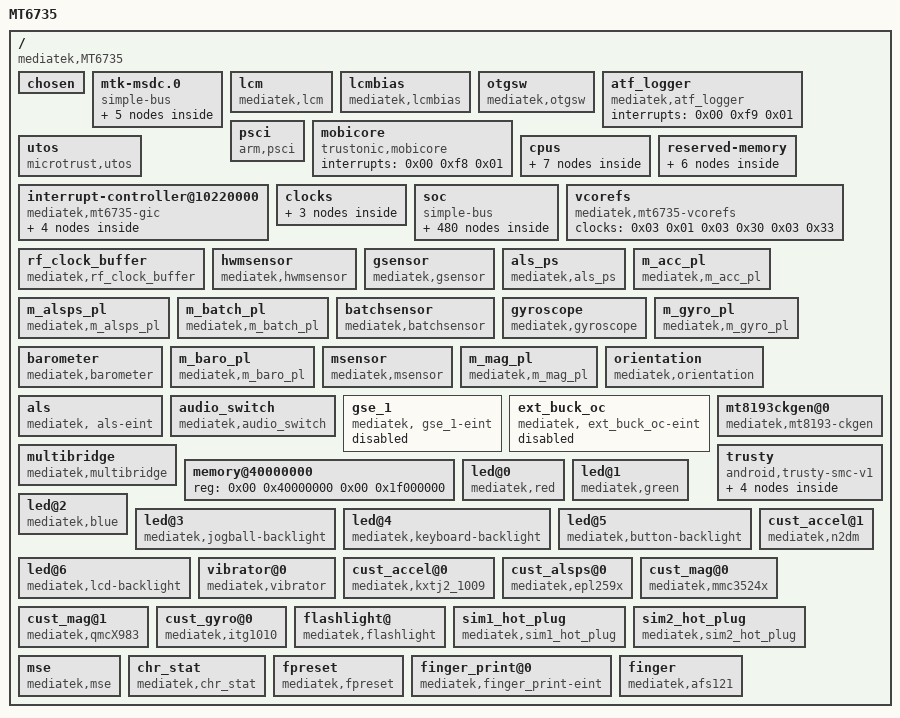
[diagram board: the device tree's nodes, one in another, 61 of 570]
/dts-v1/;

/ {
	model = "MT6735";
	compatible = "mediatek,MT6735";
	interrupt-parent = <0x01>;
	#address-cells = <0x02>;
	#size-cells = <0x02>;

	chosen {
		bootargs = "console=tty0 console=ttyMT0,921600n1 root=/dev/ram initrd=0x44000000,0x300000 loglevel=8 androidboot.hardware=mt6735";
	};

	mtk-msdc.0 {
		compatible = "simple-bus";
		#address-cells = <0x01>;
		#size-cells = <0x01>;
		ranges = <0x00 0x00 0x00 0xffffffff>;

		msdc0@11230000 {
			compatible = "mediatek,mt6735-mmc";
			reg = <0x11230000 0x10000 0x10000e84 0x02>;
			interrupts = <0x00 0x4f 0x08>;
			status = "okay";
			clocks = <0x02 0x0e 0x03 0x0d 0x03 0x29 0x03 0x2b 0x03 0x2c>;
			clock-names = "MSDC0-CLOCK\0MSDC0_PLL_SEL\0MSDC0_PLL_800M\0MSDC0_PLL_400M\0MSDC0_PLL_200M";
			clk_src = [02];
			bus-width = <0x08>;
			max-frequency = <0xbebc200>;
			cap-mmc-highspeed;
			msdc-sys-suspend;
			mmc-ddr-1_8v;
			mmc-hs200-1_8v;
			mmc-hs400-1_8v;
			non-removable;
			pinctl = <0x04>;
			register_setting = <0x05>;
			host_function = [00];
			bootable;
		};

		msdc1@11240000 {
			compatible = "mediatek,mt6735-mmc";
			reg = <0x11240000 0x10000 0x10000e84 0x02>;
			interrupts = <0x00 0x50 0x08>;
			status = "okay";
			clocks = <0x02 0x0f>;
			clock-names = "MSDC1-CLOCK";
			clk_src = [02];
			bus-width = <0x04>;
			max-frequency = <0xbebc200>;
			msdc-sys-suspend;
			cap-sd-highspeed;
			sd-uhs-sdr12;
			sd-uhs-sdr25;
			sd-uhs-sdr50;
			sd-uhs-sdr104;
			sd-uhs-ddr50;
			pinctl = <0x06>;
			pinctl_sdr104 = <0x07>;
			pinctl_sdr50 = <0x08>;
			pinctl_ddr50 = <0x09>;
			register_setting = <0x0a>;
			host_function = [01];
			cd_level = [00];
			cd-gpios = <0x0b 0x05 0x00>;
		};

		msdc2@11250000 {
			compatible = "mediatek,mt6735-mmc";
			reg = <0x11250000 0x10000 0x10000e84 0x02>;
			interrupts = <0x00 0x51 0x08>;
			status = "disabled";
			clocks = <0x02 0x10>;
			clock-names = "MSDC2-CLOCK";
		};

		msdc3@11260000 {
			compatible = "mediatek,mt6735-mmc";
			reg = <0x11260000 0x10000 0x10000e84 0x02>;
			interrupts = <0x00 0x52 0x08>;
			status = "disabled";
			clocks = <0x02 0x11>;
			clock-names = "MSDC3-CLOCK";
		};

		default {
			compatible = "mediatek, msdc1_ins-eint";
			interrupt-parent = <0x0c>;
			interrupts = <0x05 0x08>;
			debounce = <0x05 0x3e8>;
			status = "okay";
		};
	};

	lcm {
		compatible = "mediatek,lcm";
	};

	lcmbias {
		compatible = "mediatek,lcmbias";
		pinctrl-names = "default\0lcd_bias_enp0_gpio\0lcd_bias_enp1_gpio";
		pinctrl-0 = <0x0d>;
		pinctrl-1 = <0x0e>;
		pinctrl-2 = <0x0f>;
		status = "okay";
	};

	otgsw {
		compatible = "mediatek,otgsw";
		pinctrl-names = "default\0otg_switch_enp0_gpio\0otg_switch_enp1_gpio";
		pinctrl-0 = <0x0d>;
		pinctrl-1 = <0x10>;
		pinctrl-2 = <0x11>;
		status = "okay";
	};

	atf_logger {
		compatible = "mediatek,atf_logger";
		interrupts = <0x00 0xf9 0x01>;
	};

	psci {
		compatible = "arm,psci";
		method = "smc";
		cpu_suspend = <0x84000001>;
		cpu_off = <0x84000002>;
		cpu_on = <0x84000003>;
		affinity_info = <0x84000004>;
	};

	mobicore {
		compatible = "trustonic,mobicore";
		interrupts = <0x00 0xf8 0x01>;
	};

	utos {
		compatible = "microtrust,utos";
		interrupts = <0x00 0xf4 0x01 0x00 0xf5 0x01 0x00 0xf6 0x01 0x00 0xfa 0x01 0x00 0xfb 0x01 0x00 0xfc 0x01 0x00 0xfd 0x01 0x00 0xff 0x01>;
	};

	cpus {
		#address-cells = <0x01>;
		#size-cells = <0x00>;

		cpu@000 {
			device_type = "cpu";
			compatible = "arm,cortex-a53";
			reg = <0x00>;
			enable-method = "mt-boot";
			cpu-idle-states = <0x12 0x12 0x13 0x13>;
			cpu-release-addr = <0x00 0x40000200>;
			clock-frequency = "M|m";
			linux,phandle = <0x14>;
			phandle = <0x14>;
		};

		cpu@001 {
			device_type = "cpu";
			compatible = "arm,cortex-a53";
			reg = <0x01>;
			enable-method = "mt-boot";
			cpu-idle-states = <0x12 0x12 0x13 0x13>;
			cpu-release-addr = <0x00 0x40000200>;
			clock-frequency = "M|m";
			linux,phandle = <0x15>;
			phandle = <0x15>;
		};

		cpu@002 {
			device_type = "cpu";
			compatible = "arm,cortex-a53";
			reg = <0x02>;
			enable-method = "mt-boot";
			cpu-idle-states = <0x12 0x12 0x13 0x13>;
			cpu-release-addr = <0x00 0x40000200>;
			clock-frequency = "M|m";
			linux,phandle = <0x16>;
			phandle = <0x16>;
		};

		cpu@003 {
			device_type = "cpu";
			compatible = "arm,cortex-a53";
			reg = <0x03>;
			enable-method = "mt-boot";
			cpu-idle-states = <0x12 0x12 0x13 0x13>;
			cpu-release-addr = <0x00 0x40000200>;
			clock-frequency = "M|m";
			linux,phandle = <0x17>;
			phandle = <0x17>;
		};

		idle-states {
			entry-method = "arm,psci";

			cpu-sleep-0-0 {
				compatible = "arm,idle-state";
				arm,psci-suspend-param = <0x10000>;
				entry-latency-us = <0x258>;
				exit-latency-us = <0x258>;
				min-residency-us = <0x4b0>;
				linux,phandle = <0x13>;
				phandle = <0x13>;
			};

			cluster-sleep-0 {
				compatible = "arm,idle-state";
				arm,psci-suspend-param = <0x1010000>;
				entry-latency-us = <0x320>;
				exit-latency-us = <0x3e8>;
				min-residency-us = <0x7d0>;
				linux,phandle = <0x12>;
				phandle = <0x12>;
			};
		};
	};

	reserved-memory {
		#address-cells = <0x02>;
		#size-cells = <0x02>;
		ranges;

		atf-reserved-memory@43000000 {
			compatible = "mediatek,mt6735-atf-reserved-memory\0mediatek,mt6735m-atf-reserved-memory\0mediatek,mt6753-atf-reserved-memory";
			no-map;
			reg = <0x00 0x43000000 0x00 0x30000>;
		};

		ram_console-reserved-memory@43f00000 {
			compatible = "mediatek,ram_console";
			reg = <0x00 0x43f00000 0x00 0x10000>;
		};

		pstore-reserved-memory@43f10000 {
			compatible = "mediatek,pstore";
			reg = <0x00 0x43f10000 0x00 0xe0000>;
		};

		minirdump-reserved-memory@43ff0000 {
			compatible = "mediatek,minirdump";
			reg = <0x00 0x43ff0000 0x00 0x10000>;
		};

		reserve-memory-ccci_md1 {
			compatible = "mediatek,reserve-memory-ccci_md1";
			no-map;
			size = <0x00 0x3810000>;
			alignment = <0x00 0x2000000>;
			alloc-ranges = <0x00 0x40000000 0x00 0xc0000000>;
		};

		consys-reserve-memory {
			compatible = "mediatek,consys-reserve-memory";
			no-map;
			size = <0x00 0x100000>;
			alignment = <0x00 0x200000>;
		};
	};

	interrupt-controller@10220000 {
		compatible = "mediatek,mt6735-gic";
		#interrupt-cells = <0x03>;
		#address-cells = <0x00>;
		interrupt-controller;
		reg = <0x00 0x10221000 0x00 0x1000 0x00 0x10222000 0x00 0x1000 0x00 0x10200620 0x00 0x1000>;
		mediatek,wdt_irq = <0xa0>;
		linux,phandle = <0x01>;
		phandle = <0x01>;

		gic-cpuif@0 {
			compatible = "arm,gic-cpuif";
			cpuif-id = <0x00>;
			cpu = <0x14>;
		};

		gic-cpuif@1 {
			compatible = "arm,gic-cpuif";
			cpuif-id = <0x01>;
			cpu = <0x15>;
		};

		gic-cpuif@2 {
			compatible = "arm,gic-cpuif";
			cpuif-id = <0x02>;
			cpu = <0x16>;
		};

		gic-cpuif@3 {
			compatible = "arm,gic-cpuif";
			cpuif-id = <0x03>;
			cpu = <0x17>;
		};
	};

	clocks {

		clk_null {
			compatible = "fixed-clock";
			#clock-cells = <0x00>;
			clock-frequency = <0x00>;
		};

		clk26m {
			compatible = "fixed-clock";
			#clock-cells = <0x00>;
			clock-frequency = <0x18cba80>;
			linux,phandle = <0x40>;
			phandle = <0x40>;
		};

		clk32k {
			compatible = "fixed-clock";
			#clock-cells = <0x00>;
			clock-frequency = <0x7d00>;
		};
	};

	soc {
		compatible = "simple-bus";
		#address-cells = <0x01>;
		#size-cells = <0x01>;
		ranges = <0x00 0x00 0x00 0xffffffff>;

		topckgen@10210000 {
			compatible = "mediatek,mt6735-topckgen";
			reg = <0x10210000 0x1000>;
			#clock-cells = <0x01>;
			linux,phandle = <0x03>;
			phandle = <0x03>;
		};

		chipid@08000000 {
			compatible = "mediatek,chipid";
			reg = <0x8000000 0x04 0x8000004 0x04 0x8000008 0x04 0x800000c 0x04>;
		};

		infrasys@10000000 {
			compatible = "mediatek,mt6735-infrasys";
			reg = <0x10000000 0x1000>;
			#clock-cells = <0x01>;
			linux,phandle = <0x1e>;
			phandle = <0x1e>;
		};

		scpsys@10000000 {
			compatible = "mediatek,mt6735-scpsys";
			reg = <0x10000000 0x1000 0x10006000 0x1000>;
			#clock-cells = <0x01>;
			linux,phandle = <0x18>;
			phandle = <0x18>;
		};

		infracfg_ao@10000000 {
			compatible = "mediatek,infracfg_ao";
			reg = <0x10000000 0x1000>;
		};

		usb2jtag@10000000 {
			compatible = "mediatek,usb2jtag_v1";
			reg = <0x10000000 0x1000 0x11210000 0x1000>;
		};

		pwrap@10001000 {
			compatible = "mediatek,PWRAP";
			reg = <0x10001000 0x1000>;
			interrupts = <0x00 0xa3 0x04>;
		};

		perisys@10002000 {
			compatible = "mediatek,mt6735-perisys";
			reg = <0x10002000 0x1000>;
			#clock-cells = <0x01>;
			linux,phandle = <0x02>;
			phandle = <0x02>;
		};

		hacc@10008000 {
			compatible = "mediatek,hacc";
			reg = <0x10008000 0x1000>;
			interrupts = <0x00 0xae 0x08>;
		};

		pericfg@10002000 {
			compatible = "mediatek,pericfg";
			reg = <0x10002000 0x1000>;
		};

		keypad@10003000 {
			compatible = "mediatek,mt6735-keypad";
			reg = <0x10003000 0x1000>;
			interrupts = <0x00 0xa4 0x02>;
			mediatek,kpd-key-debounce = <0x400>;
			mediatek,kpd-sw-pwrkey = <0x74>;
			mediatek,kpd-hw-pwrkey = <0x08>;
			mediatek,kpd-use-extend-type = <0x00>;
			mediatek,kpd-hw-map-num = <0x48>;
			mediatek,kpd-hw-init-map = <0x72 0x73 0x00 0x00 0x00 0x00 0x00 0x00 0x00 0x00 0x00 0x00 0x00 0x00 0x00 0x00 0x00 0x00 0x00 0x00 0x00 0x00 0x00 0x00 0x00 0x00 0x00 0x00 0x00 0x00 0x00 0x00 0x00 0x00 0x00 0x00 0x00 0x00 0x00 0x00 0x00 0x00 0x00 0x00 0x00 0x00 0x00 0x00 0x00 0x00 0x00 0x00 0x00 0x00 0x00 0x00 0x00 0x00 0x00 0x00 0x00 0x00 0x00 0x00 0x00 0x00 0x00 0x00 0x00 0x00 0x00 0x00>;
			mediatek,kpd-pwrkey-eint-gpio = <0x00>;
			mediatek,kpd-pwkey-gpio-din = <0x00>;
			mediatek,kpd-hw-dl-key0 = <0x01>;
			mediatek,kpd-hw-dl-key1 = <0x00>;
			mediatek,kpd-hw-dl-key2 = <0x08>;
			mediatek,kpd-hw-recovery-key = <0x01>;
			mediatek,kpd-hw-factory-key = <0x00>;
			status = "okay";
		};

		apxgpt@10004000 {
			compatible = "mediatek,mt6735-apxgpt";
			reg = <0x10004000 0x1000>;
			interrupts = <0x00 0x98 0x08>;
			clock-frequency = <0xc65d40>;
		};

		eintc@10005000 {
			compatible = "mediatek,mt-eic";
			reg = <0x10005000 0x1000>;
			interrupts = <0x00 0x99 0x04>;
			#interrupt-cells = <0x02>;
			interrupt-controller;
			mediatek,max_eint_num = <0xd5>;
			mediatek,mapping_table_entry = <0x00>;
			mediatek,debtime_setting_entry = <0x0a>;
			mediatek,debtime_setting_array = <0x00 0x7d 0x01 0xfa 0x02 0x1f4 0x03 0x3e8 0x04 0x3e80 0x05 0x7d00 0x06 0xfa00 0x07 0x1f400 0x08 0x3e800 0x09 0x7d000>;
			linux,phandle = <0x0c>;
			phandle = <0x0c>;

			pmic@206 {
				compatible = "mediatek, pmic-eint";
				interrupt-parent = <0x0c>;
				interrupts = <0xce 0x04>;
				debounce = <0xce 0x3e8>;
			};

			MD1_SIM1_HOT_PLUG_EINT@0 {
				compatible = "mediatek,MD1_SIM1_HOT_PLUG_EINT-eint";
				interrupts = <0x00 0x04>;
				debounce = <0x00 0x186a0>;
				dedicated = <0x00 0x00>;
				src_pin = <0x00 0x01>;
				sockettype = <0x00 0x00>;
				status = "okay";
			};

			MD1_SIM2_HOT_PLUG_EINT@1 {
				compatible = "mediatek,MD1_SIM2_HOT_PLUG_EINT-eint";
				interrupts = <0x01 0x04>;
				debounce = <0x01 0x186a0>;
				dedicated = <0x01 0x00>;
				src_pin = <0x01 0x02>;
				sockettype = <0x01 0x00>;
				status = "okay";
			};
		};

		sleep@10006000 {
			compatible = "mediatek,sleep";
			reg = <0x10006000 0x1000>;
			interrupts = <0x00 0xa5 0x08 0x00 0xa6 0x08 0x00 0xa7 0x08 0x00 0xa8 0x08>;
		};

		mdcldma@1000A000 {
			compatible = "mediatek,mdcldma";
			reg = <0x1000a000 0x1000 0x1000b000 0x1000 0x1021a000 0x1000 0x1021b000 0x1000 0x1020a000 0x1000 0x1020b000 0x1000>;
			interrupts = <0x00 0x91 0x04 0x00 0x8c 0x08 0x00 0xdd 0x02>;
			mediatek,md_id = <0x00>;
			mediatek,cldma_capability = <0x06>;
			mediatek,md_smem_size = <0x10000>;
			clocks = <0x18 0x01>;
			clock-names = "scp-sys-md1-main";
			pinctrl-names = "default\0vsram_output_low\0vsram_output_high\0RFIC0_01_mode\0RFIC0_04_mode";
			pinctrl-0 = <0x19>;
			pinctrl-1 = <0x1a>;
			pinctrl-2 = <0x1b>;
			pinctrl-3 = <0x1c>;
			pinctrl-4 = <0x1d>;
		};

		mcucfg@10200000 {
			compatible = "mediatek,mcucfg";
			reg = <0x10200000 0x200>;
			interrupts = <0x00 0x47 0x04>;
		};

		cpuxgpt@10200000 {
			compatible = "mediatek,mt6735-cpuxgpt";
			reg = <0x10200000 0x1000>;
			interrupts = <0x00 0x40 0x04 0x00 0x41 0x04 0x00 0x42 0x04 0x00 0x43 0x04 0x00 0x44 0x04 0x00 0x45 0x04 0x00 0x46 0x04 0x00 0x47 0x04>;
		};

		lastpc@10200000 {
			compatible = "mediatek,mt6735-mcucfg";
			reg = <0x10200000 0x200>;
			interrupts = <0x00 0x47 0x04>;
		};

		emi@10203000 {
			compatible = "mediatek,emi";
			reg = <0x10203000 0x1000>;
			interrupts = <0x00 0x88 0x04>;
		};

		sys_cirq@10204000 {
			compatible = "mediatek,mt6735-sys_cirq";
			reg = <0x10204000 0x1000>;
			interrupts = <0x00 0xe7 0x08>;
			mediatek,cirq_num = <0x9f>;
			mediatek,spi_start_offset = <0x48>;
		};

		m4u@10205000 {
			cell-index = <0x00>;
			compatible = "mediatek,m4u";
			reg = <0x10205000 0x1000>;
			interrupts = <0x00 0x92 0x08>;
			clocks = <0x1e 0x09 0x1f 0x01 0x1f 0x02 0x20 0x01 0x20 0x02 0x21 0x01 0x22 0x02 0x22 0x01>;
			clock-names = "infra_m4u\0smi_common\0m4u_disp0_smi_larb0\0m4u_vdec0_vdec\0m4u_vdec1_larb\0m4u_img_image_larb2_smi\0m4u_venc_venc\0m4u_venc_larb";
		};

		efusec@10206000 {
			compatible = "mediatek,efusec";
			reg = <0x10206000 0x1000>;
		};

		devapc@10207000 {
			compatible = "mediatek,devapc";
			reg = <0x10207000 0x1000>;
			interrupts = <0x00 0x86 0x08>;
			clocks = <0x1e 0x05>;
			clock-names = "devapc-main";
		};

		bus_dbg@10208000 {
			compatible = "mediatek,bus_dbg-v1";
			reg = <0x10208000 0x1000>;
			interrupts = <0x00 0x89 0x08>;
		};

		apmixedsys@10209000 {
			compatible = "mediatek,mt6735-apmixedsys";
			reg = <0x10209000 0x1000>;
			#clock-cells = <0x01>;
			linux,phandle = <0x3f>;
			phandle = <0x3f>;
		};

		apmixed@10209000 {
			compatible = "mediatek,apmixed";
			reg = <0x10209000 0x1000>;
		};

		fhctl@10209f00 {
			compatible = "mediatek,fhctl";
			reg = <0x10209f00 0x100>;
		};

		dramc_nao@1020e000 {
			compatible = "mediatek,mt6735-dramc_nao";
			reg = <0x1020e000 0x1000>;
		};

		cksys@10210000 {
			compatible = "mediatek,cksys";
			reg = <0x10210000 0x1000>;
		};

		syscfg_pctl_a@10211000 {
			compatible = "mediatek,mt6735-pctl-a-syscfg\0syscon";
			reg = <0x00 0x9bceb8 0x00 0x3e8>;
			linux,phandle = <0x23>;
			phandle = <0x23>;
		};

		pinctrl@10211000 {
			compatible = "mediatek,mt6735-pinctrl";
			reg = <0x00 0x9bceb8 0x00 0x3e8>;
			mediatek,pctl-regmap = <0x23>;
			pins-are-numbered;
			gpio-controller;
			#gpio-cells = <0x02>;
			linux,phandle = <0x0b>;
			phandle = <0x0b>;

			8193ckgen_default {
				linux,phandle = <0x97>;
				phandle = <0x97>;
			};

			8193ckgen_gpio {
				linux,phandle = <0x98>;
				phandle = <0x98>;

				pins_cmd_dat {
					pins = <0x00>;
					slew-rate = <0x01>;
					bias-pull-up = <0x00>;
					output-high;
				};
			};

			8193ckgen_dpi {
				linux,phandle = <0x99>;
				phandle = <0x99>;

				pins_cmd_dat {
					pins = <0x02>;
				};
			};

			ssw0default {
				linux,phandle = <0x7c>;
				phandle = <0x7c>;
			};

			ssw@1 {
				linux,phandle = <0x7d>;
				phandle = <0x7d>;

				pins_cmd0_dat {
					pins = <0x805>;
				};

				pins_cmd1_dat {
					pins = <0x904>;
				};
			};

			ssw@2 {
				linux,phandle = <0x7e>;
				phandle = <0x7e>;

				pins_cmd0_dat {
					pins = <0x802>;
				};

				pins_cmd1_dat {
					pins = <0x904>;
				};
			};

			ssw@3 {
				linux,phandle = <0x7f>;
				phandle = <0x7f>;

				pins_cmd0_dat {
					pins = <0xa301>;
					slew-rate = <0x01>;
				};

				pins_cmd1_dat {
					pins = <0xa401>;
					slew-rate = <0x01>;
				};

				pins_cmd2_dat {
					pins = <0xa501>;
					slew-rate = <0x00>;
					bias-pull-up = <0x00>;
				};

				pins_cmd3_dat {
					pins = <0xa001>;
					slew-rate = <0x01>;
				};

				pins_cmd4_dat {
					pins = <0xa101>;
					slew-rate = <0x01>;
				};

				pins_cmd5_dat {
					pins = <0xa201>;
					slew-rate = <0x00>;
					bias-pull-up = <0x00>;
				};
			};

			ssw@4 {
				linux,phandle = <0x80>;
				phandle = <0x80>;

				pins_cmd0_dat {
					pins = <0xa304>;
				};

				pins_cmd1_dat {
					pins = <0xa404>;
				};

				pins_cmd2_dat {
					pins = <0xa504>;
				};

				pins_cmd3_dat {
					pins = <0xa001>;
				};

				pins_cmd4_dat {
					pins = <0xa101>;
				};

				pins_cmd5_dat {
					pins = <0xa201>;
				};
			};

			vsram0default {
				linux,phandle = <0x19>;
				phandle = <0x19>;
			};

			vsram@1 {
				linux,phandle = <0x1a>;
				phandle = <0x1a>;

				pins_cmd_dat {
					pins = <0x8c00>;
					slew-rate = <0x01>;
					output-low;
				};
			};

			vsram@2 {
				linux,phandle = <0x1b>;
				phandle = <0x1b>;

				pins_cmd_dat {
					pins = <0x8c00>;
					slew-rate = <0x01>;
					output-high;
				};
			};

			clockbuf@1 {
				linux,phandle = <0x1c>;
				phandle = <0x1c>;

				pins_cmd0_dat {
					pins = <0x6e01>;
				};

				pins_cmd1_dat {
					pins = <0x6f01>;
				};

				pins_cmd2_dat {
					pins = <0x7001>;
				};

				pins_cmd3_dat {
					pins = <0x7101>;
				};

				pins_cmd4_dat {
					pins = <0x7201>;
				};
			};

			clockbuf@2 {
				linux,phandle = <0x1d>;
				phandle = <0x1d>;

				pins_cmd0_dat {
					pins = <0x6e04>;
				};

				pins_cmd1_dat {
					pins = <0x6f04>;
				};

				pins_cmd2_dat {
					pins = <0x7004>;
				};

				pins_cmd3_dat {
					pins = <0x7104>;
				};

				pins_cmd4_dat {
					pins = <0x7204>;
				};
			};

			uart0gpiodefault {
				linux,phandle = <0x26>;
				phandle = <0x26>;
			};

			uart0_rx_set@gpio74 {
				linux,phandle = <0x27>;
				phandle = <0x27>;

				pins_cmd_dat {
					pins = <0x4a01>;
				};
			};

			uart0_rx_clear@gpio74 {
				linux,phandle = <0x28>;
				phandle = <0x28>;

				pins_cmd_dat {
					pins = <0x4a00>;
					slew-rate = <0x01>;
					output-high;
				};
			};

			uart0_tx_set@gpio75 {
				linux,phandle = <0x29>;
				phandle = <0x29>;

				pins_cmd_dat {
					pins = <0x4b01>;
				};
			};

			uart0_tx_clear@gpio75 {
				linux,phandle = <0x2a>;
				phandle = <0x2a>;

				pins_cmd_dat {
					pins = <0x4b00>;
					slew-rate = <0x01>;
					output-high;
				};
			};

			uart1gpiodefault {
				linux,phandle = <0x2b>;
				phandle = <0x2b>;
			};

			uart1_rx_set@gpio76 {

				pins_cmd_dat {
					pins = <0x4c01>;
				};
			};

			uart1_rx_clear@gpio76 {

				pins_cmd_dat {
					pins = <0x4c00>;
					slew-rate = <0x01>;
					output-high;
				};
			};

			uart1_tx_set@gpio77 {
				linux,phandle = <0x2c>;
				phandle = <0x2c>;

				pins_cmd_dat {
					pins = <0x4d01>;
				};
			};

			uart1_tx_clear@gpio77 {
				linux,phandle = <0x2d>;
				phandle = <0x2d>;

				pins_cmd_dat {
					pins = <0x4d00>;
					slew-rate = <0x01>;
					output-high;
				};
			};

			uart2gpiodefault {
				linux,phandle = <0x2e>;
				phandle = <0x2e>;
			};

			uart2_rx_set@gpio57 {
				linux,phandle = <0x2f>;
				phandle = <0x2f>;

				pins_cmd_dat {
					pins = <0x3901>;
				};
			};

			uart2_rx_clear@gpio57 {
				linux,phandle = <0x30>;
				phandle = <0x30>;

				pins_cmd_dat {
					pins = <0x3900>;
					slew-rate = <0x01>;
					output-high;
				};
			};

			uart2_tx_set@gpio58 {
				linux,phandle = <0x31>;
				phandle = <0x31>;

				pins_cmd_dat {
					pins = <0x3a01>;
				};
			};

			uart2_tx_clear@gpio58 {
				linux,phandle = <0x32>;
				phandle = <0x32>;

				pins_cmd_dat {
					pins = <0x3a00>;
					slew-rate = <0x01>;
					output-high;
				};
			};

			uart3gpiodefault {
				linux,phandle = <0x33>;
				phandle = <0x33>;
			};

			uart3_rx_set@gpio59 {
				linux,phandle = <0x34>;
				phandle = <0x34>;

				pins_cmd_dat {
					pins = <0x3b01>;
				};
			};

			uart3_rx_clear@gpio59 {
				linux,phandle = <0x35>;
				phandle = <0x35>;

				pins_cmd_dat {
					pins = <0x3b00>;
					slew-rate = <0x01>;
					output-high;
				};
			};

			uart3_tx_set@gpio60 {
				linux,phandle = <0x36>;
				phandle = <0x36>;

				pins_cmd_dat {
					pins = <0x3c01>;
				};
			};

			uart3_tx_clear@gpio60 {
				linux,phandle = <0x37>;
				phandle = <0x37>;

				pins_cmd_dat {
					pins = <0x3c00>;
					slew-rate = <0x01>;
					output-high;
				};
			};

			irtx_gpio_led_def@gpio19 {
				linux,phandle = <0x24>;
				phandle = <0x24>;

				pins_cmd_dat {
					pins = <0x1300>;
					slew-rate = <0x01>;
					bias-disable;
					output-high;
					input-schmitt-enable = <0x00>;
				};
			};

			irtx_gpio_led_set@gpio19 {
				linux,phandle = <0x25>;
				phandle = <0x25>;

				pins_cmd_dat {
					pins = <0x1302>;
				};
			};

			alspspincfg {
				linux,phandle = <0x94>;
				phandle = <0x94>;

				pins_cmd_dat {
					pins = <0x4d00>;
					slew-rate = <0x00>;
					bias-pull-up = <0x00>;
				};
			};

			alspsdefaultcfg {
				linux,phandle = <0x93>;
				phandle = <0x93>;
			};

			gyropincfg {
				linux,phandle = <0x96>;
				phandle = <0x96>;

				pins_cmd_dat {
					pins = <0x4300>;
					slew-rate = <0x00>;
					bias-pull-down = <0x00>;
				};
			};

			gyrodefaultcfg {
				linux,phandle = <0x95>;
				phandle = <0x95>;
			};

			eint0default {
				linux,phandle = <0x6d>;
				phandle = <0x6d>;
			};

			eint@0 {
				linux,phandle = <0x6e>;
				phandle = <0x6e>;

				pins_cmd_dat {
					pins = <0xa00>;
					slew-rate = <0x00>;
					bias-pull-up = <0x00>;
				};
			};

			eintoutput0 {
				linux,phandle = <0x6f>;
				phandle = <0x6f>;

				pins_cmd_dat {
					pins = <0xa00>;
					slew-rate = <0x01>;
					output-low;
				};
			};

			eintoutput1 {
				linux,phandle = <0x70>;
				phandle = <0x70>;

				pins_cmd_dat {
					pins = <0xa00>;
					slew-rate = <0x01>;
					output-high;
				};
			};

			rstoutput0 {
				linux,phandle = <0x71>;
				phandle = <0x71>;

				pins_cmd_dat {
					pins = <0x3e00>;
					slew-rate = <0x01>;
					output-low;
				};
			};

			rstoutput1 {
				linux,phandle = <0x72>;
				phandle = <0x72>;

				pins_cmd_dat {
					pins = <0x3e00>;
					slew-rate = <0x01>;
					output-high;
				};
			};

			flashlightdefault {
				linux,phandle = <0x9a>;
				phandle = <0x9a>;
			};

			enableoutput0 {
				linux,phandle = <0x9b>;
				phandle = <0x9b>;

				pins_cmd_dat {
					pins = <0x2a00>;
					slew-rate = <0x01>;
					output-low;
				};
			};

			enableoutput1 {
				linux,phandle = <0x9c>;
				phandle = <0x9c>;

				pins_cmd_dat {
					pins = <0x2a00>;
					slew-rate = <0x01>;
					output-high;
				};
			};

			modeoutput0 {
				linux,phandle = <0x9d>;
				phandle = <0x9d>;

				pins_cmd_dat {
					pins = <0x100>;
					slew-rate = <0x01>;
					output-low;
				};
			};

			modeoutput1 {
				linux,phandle = <0x9e>;
				phandle = <0x9e>;

				pins_cmd_dat {
					pins = <0x100>;
					slew-rate = <0x01>;
					output-high;
				};
			};

			pwmoutput {
				linux,phandle = <0x9f>;
				phandle = <0x9f>;

				pins_cmd_dat {
					pins = <0x101>;
					slew-rate = <0x01>;
				};
			};

			charger_red_GPIO_output {
				linux,phandle = <0xa0>;
				phandle = <0xa0>;

				pins_cmd_dat {
					pins = <0x3900>;
					slew-rate = <0x01>;
					output-high;
				};
			};

			audiodefault {
				linux,phandle = <0x41>;
				phandle = <0x41>;
			};

			pmicclkmode0 {
				linux,phandle = <0x42>;
				phandle = <0x42>;

				pins_cmd0_dat {
					pins = <0x8f00>;
				};

				pins_cmd1_dat {
					pins = <0x9000>;
				};

				pins_cmd2_dat {
					pins = <0x9100>;
				};
			};

			pmicclkmode1 {
				linux,phandle = <0x43>;
				phandle = <0x43>;

				pins_cmd0_dat {
					pins = <0x8f01>;
				};

				pins_cmd1_dat {
					pins = <0x9001>;
				};

				pins_cmd2_dat {
					pins = <0x9101>;
				};
			};

			audi2s1mode0 {
				linux,phandle = <0x44>;
				phandle = <0x44>;

				pins_cmd0_dat {
					pins = <0x4e00>;
				};

				pins_cmd1_dat {
					pins = <0x4f00>;
				};

				pins_cmd2_dat {
					pins = <0x5000>;
				};
			};

			audi2s1mode1 {
				linux,phandle = <0x45>;
				phandle = <0x45>;

				pins_cmd0_dat {
					pins = <0x4e01>;
				};

				pins_cmd1_dat {
					pins = <0x4f01>;
				};

				pins_cmd2_dat {
					pins = <0x5001>;
				};
			};

			audexamphigh {
				linux,phandle = <0x46>;
				phandle = <0x46>;

				pins_cmd_dat {
					pins = <0x8100>;
					slew-rate = <0x01>;
					output-high;
				};
			};

			audexamplow {
				linux,phandle = <0x47>;
				phandle = <0x47>;

				pins_cmd_dat {
					pins = <0x8100>;
					slew-rate = <0x01>;
					output-low;
				};
			};

			audexam2phigh {
				linux,phandle = <0x48>;
				phandle = <0x48>;

				pins_cmd_dat {
					pins = <0x8000>;
					slew-rate = <0x01>;
					output-high;
				};
			};

			audexamp2low {
				linux,phandle = <0x49>;
				phandle = <0x49>;

				pins_cmd_dat {
					pins = <0x8000>;
					slew-rate = <0x01>;
					output-low;
				};
			};

			audrcvspkhigh {
				linux,phandle = <0x4a>;
				phandle = <0x4a>;

				pins_cmd_dat {
					pins = <0x7800>;
					slew-rate = <0x01>;
					output-high;
				};
			};

			audrcvspklow {
				linux,phandle = <0x4b>;
				phandle = <0x4b>;

				pins_cmd_dat {
					pins = <0x7800>;
					slew-rate = <0x01>;
					output-low;
				};
			};

			cam0@0 {
				linux,phandle = <0x5b>;
				phandle = <0x5b>;

				pins_cmd_dat {
					pins = <0x2c00>;
					slew-rate = <0x01>;
					output-low;
				};
			};

			cam0@1 {
				linux,phandle = <0x5c>;
				phandle = <0x5c>;

				pins_cmd_dat {
					pins = <0x2c00>;
					slew-rate = <0x01>;
					output-high;
				};
			};

			cam0@2 {
				linux,phandle = <0x5d>;
				phandle = <0x5d>;

				pins_cmd_dat {
					pins = <0x700>;
					slew-rate = <0x01>;
					output-low;
				};
			};

			cam0@3 {
				linux,phandle = <0x5e>;
				phandle = <0x5e>;

				pins_cmd_dat {
					pins = <0x700>;
					slew-rate = <0x01>;
					output-high;
				};
			};

			cam1@0 {
				linux,phandle = <0x5f>;
				phandle = <0x5f>;

				pins_cmd_dat {
					pins = <0xb00>;
					slew-rate = <0x01>;
					output-low;
				};
			};

			cam1@1 {
				linux,phandle = <0x60>;
				phandle = <0x60>;

				pins_cmd_dat {
					pins = <0xb00>;
					slew-rate = <0x01>;
					output-high;
				};
			};

			cam1@2 {
				linux,phandle = <0x61>;
				phandle = <0x61>;

				pins_cmd_dat {
					pins = <0xc00>;
					slew-rate = <0x01>;
					output-low;
				};
			};

			cam1@3 {
				linux,phandle = <0x62>;
				phandle = <0x62>;

				pins_cmd_dat {
					pins = <0xc00>;
					slew-rate = <0x01>;
					output-high;
				};
			};

			cam@0 {
				linux,phandle = <0x63>;
				phandle = <0x63>;

				pins_cmd_dat {
					pins = <0x4400>;
					slew-rate = <0x01>;
					output-low;
				};
			};

			cam@1 {
				linux,phandle = <0x64>;
				phandle = <0x64>;

				pins_cmd_dat {
					pins = <0x4400>;
					slew-rate = <0x01>;
					output-high;
				};
			};

			camdefault {
				linux,phandle = <0x5a>;
				phandle = <0x5a>;
			};

			default {
				linux,phandle = <0x0d>;
				phandle = <0x0d>;
			};

			gpslna@0 {
				linux,phandle = <0x69>;
				phandle = <0x69>;

				pins_cmd_dat {
					pins = <0x4f00>;
					slew-rate = <0x00>;
					bias-disable;
					output-low;
				};
			};

			gpslna@1 {
				linux,phandle = <0x6a>;
				phandle = <0x6a>;

				pins_cmd_dat {
					pins = <0x4f00>;
					slew-rate = <0x01>;
					output-high;
				};
			};

			gpslna@2 {
				linux,phandle = <0x6b>;
				phandle = <0x6b>;

				pins_cmd_dat {
					pins = <0x4f00>;
					slew-rate = <0x01>;
					output-low;
				};
			};

			mmc0@default {
				linux,phandle = <0x04>;
				phandle = <0x04>;

				pins_cmd {
					drive-strength = [02];
				};

				pins_dat {
					drive-strength = [02];
				};

				pins_clk {
					drive-strength = [02];
				};

				pins_rst {
					drive-strength = [02];
				};

				pins_ds {
					drive-strength = [02];
				};
			};

			mmc0@register_default {
				dat0rddly = [00];
				dat1rddly = [00];
				dat2rddly = [00];
				dat3rddly = [00];
				dat4rddly = [00];
				dat5rddly = [00];
				dat6rddly = [00];
				dat7rddly = [00];
				datwrddly = [00];
				cmdrrddly = [00];
				cmdrddly = [00];
				cmd_edge = [01];
				rdata_edge = [01];
				wdata_edge = [01];
				ett-hs200-cells = <0x0c>;
				ett-hs200-default = <0xb0 0x380 0x00 0xb0 0x7c00 0x00 0xb4 0x38 0x01 0x04 0x02 0x00 0xf0 0x1f0000 0x07 0xf0 0x7c00000 0x0b 0xb4 0x07 0x01 0xf0 0x1f 0x0b 0x04 0x400 0x00 0xf8 0x1f000000 0x07 0xf0 0x1f00 0x09 0x04 0x04 0x00>;
				ett-hs400-cells = <0x08>;
				ett-hs400-default = <0xb0 0x380 0x00 0xb0 0x7c00 0x00 0x188 0x7c 0x02 0x188 0x1f000 0x10 0xb4 0x38 0x01 0x04 0x02 0x00 0xf0 0x1f0000 0x06 0xf0 0x7c00000 0x06>;
				linux,phandle = <0x05>;
				phandle = <0x05>;
			};

			mmc1@default {
				linux,phandle = <0x06>;
				phandle = <0x06>;

				pins_cmd {
					drive-strength = [03];
				};

				pins_dat {
					drive-strength = [03];
				};

				pins_clk {
					drive-strength = [03];
				};
			};

			mmc1@sdr104 {
				linux,phandle = <0x07>;
				phandle = <0x07>;

				pins_cmd {
					drive-strength = [02];
				};

				pins_dat {
					drive-strength = [02];
				};

				pins_clk {
					drive-strength = [03];
				};
			};

			mmc1@sdr50 {
				linux,phandle = <0x08>;
				phandle = <0x08>;

				pins_cmd {
					drive-strength = [02];
				};

				pins_dat {
					drive-strength = [02];
				};

				pins_clk {
					drive-strength = [03];
				};
			};

			mmc1@ddr50 {
				linux,phandle = <0x09>;
				phandle = <0x09>;

				pins_cmd {
					drive-strength = [02];
				};

				pins_dat {
					drive-strength = [02];
				};

				pins_clk {
					drive-strength = [03];
				};
			};

			mmc1@register_default {
				dat0rddly = [00];
				dat1rddly = [00];
				dat2rddly = [00];
				dat3rddly = [00];
				datwrddly = [00];
				cmdrrddly = [00];
				cmdrddly = [00];
				cmd_edge = [01];
				rdata_edge = [01];
				wdata_edge = [01];
				linux,phandle = <0x0a>;
				phandle = <0x0a>;
			};

			state_ven_high {
				linux,phandle = <0x75>;
				phandle = <0x75>;

				pins_cmd_dat {
					pins = <0x400>;
					slew-rate = <0x01>;
					output-high;
				};
			};

			state_ven_low {
				linux,phandle = <0x76>;
				phandle = <0x76>;

				pins_cmd_dat {
					pins = <0x400>;
					slew-rate = <0x01>;
					output-low;
				};
			};

			state_rst_high {
				linux,phandle = <0x77>;
				phandle = <0x77>;

				pins_cmd_dat {
					pins = <0x300>;
					slew-rate = <0x01>;
					output-high;
				};
			};

			state_rst_low {
				linux,phandle = <0x78>;
				phandle = <0x78>;

				pins_cmd_dat {
					pins = <0x300>;
					slew-rate = <0x01>;
					output-low;
				};
			};

			state_eint_high {
				linux,phandle = <0x79>;
				phandle = <0x79>;

				pins_cmd_dat {
					pins = <0x100>;
					slew-rate = <0x01>;
					output-high;
				};
			};

			state_eint_low {
				linux,phandle = <0x7a>;
				phandle = <0x7a>;

				pins_cmd_dat {
					pins = <0x100>;
					slew-rate = <0x01>;
					output-low;
				};
			};

			state_irq_init {
				linux,phandle = <0x7b>;
				phandle = <0x7b>;

				pins_cmd_dat {
					pins = <0x200>;
					slew-rate = <0x00>;
					bias-pull-down = <0x00>;
				};
			};

			usb_default {
				linux,phandle = <0x39>;
				phandle = <0x39>;
			};

			iddig_irq_init {
				linux,phandle = <0x3a>;
				phandle = <0x3a>;

				pins_cmd_dat {
					pins = <0x01>;
					slew-rate = <0x00>;
					bias-pull-up = <0x00>;
				};
			};

			drvvbus_init {
				linux,phandle = <0x3b>;
				phandle = <0x3b>;

				pins_cmd_dat {
					pins = <0x5300>;
					slew-rate = <0x01>;
					bias-pull-down = <0x00>;
				};
			};

			drvvbus_low {
				linux,phandle = <0x3c>;
				phandle = <0x3c>;

				pins_cmd_dat {
					pins = <0x5300>;
					slew-rate = <0x01>;
					output-low;
					bias-pull-down = <0x00>;
				};
			};

			drvvbus_high {
				linux,phandle = <0x3d>;
				phandle = <0x3d>;

				pins_cmd_dat {
					pins = <0x5300>;
					slew-rate = <0x01>;
					output-high;
					bias-pull-down = <0x00>;
				};
			};

			lcm_mode_default {
				linux,phandle = <0x4d>;
				phandle = <0x4d>;

				pins_cmd_dat {
					pins = <0x5000>;
				};
			};

			lcm_mode@0 {
				linux,phandle = <0x4e>;
				phandle = <0x4e>;

				pins_cmd_dat {
					pins = <0x5000>;
				};
			};

			lcm_mode@1 {
				linux,phandle = <0x4f>;
				phandle = <0x4f>;

				pins_cmd_dat {
					pins = <0x5001>;
				};
			};

			lcm_mode@2 {
				linux,phandle = <0x50>;
				phandle = <0x50>;

				pins_cmd_dat {
					pins = <0x5002>;
				};
			};

			lcm_mode@3 {
				linux,phandle = <0x51>;
				phandle = <0x51>;

				pins_cmd_dat {
					pins = <0x5003>;
				};
			};

			lcm_mode@4 {
				linux,phandle = <0x52>;
				phandle = <0x52>;

				pins_cmd_dat {
					pins = <0x5004>;
				};
			};

			lcm_mode@5 {
				linux,phandle = <0x53>;
				phandle = <0x53>;

				pins_cmd_dat {
					pins = <0x5005>;
				};
			};

			lcm_mode@6 {
				linux,phandle = <0x54>;
				phandle = <0x54>;

				pins_cmd_dat {
					pins = <0x5006>;
				};
			};

			lcm_mode@7 {
				linux,phandle = <0x55>;
				phandle = <0x55>;

				pins_cmd_dat {
					pins = <0x5007>;
				};
			};

			lcd_bias_enp0_gpio {
				linux,phandle = <0x0e>;
				phandle = <0x0e>;

				pins_cmd_dat {
					pins = <0x7700>;
					slew-rate = <0x01>;
					output-low;
				};
			};

			lcd_bias_enp1_gpio {
				linux,phandle = <0x0f>;
				phandle = <0x0f>;

				pins_cmd_dat {
					pins = <0x7700>;
					slew-rate = <0x01>;
					output-high;
				};
			};

			otg_switch_enp0_gpio {
				linux,phandle = <0x10>;
				phandle = <0x10>;

				pins_cmd_dat {
					pins = <0x300>;
					slew-rate = <0x01>;
					output-low;
				};
			};

			otg_switch_enp1_gpio {
				linux,phandle = <0x11>;
				phandle = <0x11>;

				pins_cmd_dat {
					pins = <0x300>;
					slew-rate = <0x01>;
					output-high;
				};
			};

			eint6default {
				linux,phandle = <0x73>;
				phandle = <0x73>;
			};

			eint@6 {
				linux,phandle = <0x74>;
				phandle = <0x74>;

				pins_cmd_dat {
					pins = <0x600>;
					slew-rate = <0x00>;
					bias-disable;
				};
			};

			spi_default {
				linux,phandle = <0xa1>;
				phandle = <0xa1>;
			};

			finger_rst_low {
				linux,phandle = <0xa2>;
				phandle = <0xa2>;

				pins_cmd_dat {
					pins = <0x7a00>;
					slew-rate = <0x01>;
					output-low;
				};
			};

			finger_rst_high {
				linux,phandle = <0xa3>;
				phandle = <0xa3>;

				pins_cmd_dat {
					pins = <0x7a00>;
					slew-rate = <0x01>;
					output-high;
				};
			};

			spi_cs_low {
				linux,phandle = <0xa4>;
				phandle = <0xa4>;

				pins_cmd_dat {
					pins = <0x4101>;
					slew-rate = <0x01>;
					output-low;
				};
			};

			spi_cs_high {
				linux,phandle = <0xa5>;
				phandle = <0xa5>;

				pins_cmd_dat {
					pins = <0x4101>;
					slew-rate = <0x01>;
					output-high;
				};
			};

			spi_mi_low {
				linux,phandle = <0xa6>;
				phandle = <0xa6>;

				pins_cmd_dat {
					pins = <0x4301>;
					slew-rate = <0x00>;
					bias-pull-up = <0x00>;
				};
			};

			spi_mi_high {
				linux,phandle = <0xa7>;
				phandle = <0xa7>;

				pins_cmd_dat {
					pins = <0x4301>;
					bias-disable;
				};
			};

			spi_mo_low {
				linux,phandle = <0xa8>;
				phandle = <0xa8>;

				pins_cmd_dat {
					pins = <0x4401>;
					slew-rate = <0x01>;
					output-low;
				};
			};

			spi_mo_high {
				linux,phandle = <0xa9>;
				phandle = <0xa9>;

				pins_cmd_dat {
					pins = <0x4401>;
					slew-rate = <0x01>;
					output-high;
				};
			};

			spi_mclk_low {
				linux,phandle = <0xaa>;
				phandle = <0xaa>;

				pins_cmd_dat {
					pins = <0x4201>;
					slew-rate = <0x01>;
					output-low;
				};
			};

			spi_mclk_high {
				linux,phandle = <0xab>;
				phandle = <0xab>;

				pins_cmd_dat {
					pins = <0x4201>;
					slew-rate = <0x01>;
					output-high;
				};
			};

			eint {
				linux,phandle = <0xac>;
				phandle = <0xac>;

				pins_cmd_dat {
					pins = <0x7900>;
					slew-rate = <0x00>;
					bias-disable;
				};
			};

			eint_in_low {
				linux,phandle = <0xad>;
				phandle = <0xad>;

				pins_cmd_dat {
					pins = <0x7900>;
					slew-rate = <0x00>;
					bias-pull-down = <0x00>;
				};
			};

			eint_in_float {
				linux,phandle = <0xae>;
				phandle = <0xae>;

				pins_cmd_dat {
					pins = <0x7900>;
					slew-rate = <0x00>;
					bias-disable;
				};
			};
		};

		gpio {
			compatible = "mediatek,gpio_usage_mapping";
			GPIO_SIM1_HOT_PLUG = <0x08>;
			GPIO_SIM2_HOT_PLUG = <0x09>;
			GPIO_SIM2_SCLK = <0xa0>;
			GPIO_SIM2_SRST = <0xa1>;
			GPIO_SIM2_SIO = <0xa2>;
			GPIO_SIM1_SCLK = <0xa3>;
			GPIO_SIM1_SRST = <0xa4>;
			GPIO_SIM1_SIO = <0xa5>;
		};

		gpio@10211000 {
			compatible = "mediatek,gpio";
			reg = <0x10211000 0x1000>;
		};

		toprgu@10212000 {
			compatible = "mediatek,mt6735-rgu";
			reg = <0x10212000 0x1000>;
			interrupts = <0x00 0x80 0x02>;
		};

		ddrphy@10213000 {
			compatible = "mediatek,mt6735-ddrphy";
			reg = <0x10213000 0x1000>;
		};

		dramc@10214000 {
			compatible = "mediatek,mt6735-dramc";
			reg = <0x10214000 0x1000>;
			clocks = <0x1e 0x02>;
			clock-names = "infra-cqdma";
		};

		gcpu@10216000 {
			compatible = "mediatek,gcpu";
			reg = <0x10216000 0x1000>;
			interrupts = <0x00 0x96 0x08>;
		};

		gce@10217000 {
			compatible = "mediatek,gce";
			reg = <0x10217000 0x1000>;
			interrupts = <0x00 0x97 0x08 0x00 0x94 0x08>;
			disp_mutex_reg = <0x14014000 0x1000>;
			g3d_config_base = <0x13000000 0x00 0xffff0000>;
			mmsys_config_base = <0x14000000 0x01 0xffff0000>;
			disp_dither_base = <0x14010000 0x02 0xffff0000>;
			mm_na_base = <0x14020000 0x03 0xffff0000>;
			imgsys_base = <0x15000000 0x04 0xffff0000>;
			vdec_gcon_base = <0x16000000 0x05 0xffff0000>;
			venc_gcon_base = <0x17000000 0x06 0xffff0000>;
			conn_peri_base = <0x18000000 0x07 0xffff0000>;
			topckgen_base = <0x10000000 0x08 0xffff0000>;
			kp_base = <0x10010000 0x09 0xffff0000>;
			scp_sram_base = <0x10020000 0x0a 0xffff0000>;
			infra_na3_base = <0x10030000 0x0b 0xffff0000>;
			infra_na4_base = <0x10040000 0x0c 0xffff0000>;
			scp_base = <0x10050000 0x0d 0xffff0000>;
			mcucfg_base = <0x10200000 0x0e 0xffff0000>;
			gcpu_base = <0x10210000 0x0f 0xffff0000>;
			usb0_base = <0x11200000 0x10 0xffff0000>;
			usb_sif_base = <0x11210000 0x11 0xffff0000>;
			audio_base = <0x11220000 0x12 0xffff0000>;
			msdc0_base = <0x11230000 0x13 0xffff0000>;
			msdc1_base = <0x11240000 0x14 0xffff0000>;
			msdc2_base = <0x11250000 0x15 0xffff0000>;
			msdc3_base = <0x11260000 0x16 0xffff0000>;
			pwm_sw_base = <0x1100e000 0x63 0xfffff000>;
			mdp_rdma0_sof = <0x00>;
			mdp_rsz0_sof = <0x01>;
			mdp_rsz1_sof = <0x02>;
			dsi0_te_event = <0x03>;
			mdp_wdma_sof = <0x04>;
			mdp_wrot_sof = <0x05>;
			disp_ovl0_sof = <0x06>;
			disp_rdma0_sof = <0x07>;
			disp_rdma1_sof = <0x08>;
			disp_wdma0_sof = <0x09>;
			disp_ccorr_sof = <0x0a>;
			disp_color_sof = <0x0b>;
			disp_aal_sof = <0x0c>;
			disp_gamma_sof = <0x0d>;
			disp_dither_sof = <0x0e>;
			disp_pwm0_sof = <0x10>;
			mdp_rdma0_frame_done = <0x11>;
			mdp_rsz0_frame_done = <0x12>;
			mdp_rsz1_frame_done = <0x13>;
			mdp_tdshp_frame_done = <0x14>;
			mdp_wdma_frame_done = <0x15>;
			mdp_wrot_write_frame_done = <0x16>;
			mdp_wrot_read_frame_done = <0x17>;
			disp_ovl0_frame_done = <0x18>;
			disp_rdma0_frame_done = <0x19>;
			disp_rdma1_frame_done = <0x1a>;
			disp_wdma0_frame_done = <0x1b>;
			disp_ccorr_frame_done = <0x1c>;
			disp_color_frame_done = <0x1d>;
			disp_aal_frame_done = <0x1e>;
			disp_gamma_frame_done = <0x1f>;
			disp_dither_frame_done = <0x20>;
			disp_dpi0_frame_done = <0x22>;
			stream_done_0 = <0x23>;
			stream_done_1 = <0x24>;
			stream_done_2 = <0x25>;
			stream_done_3 = <0x26>;
			stream_done_4 = <0x27>;
			stream_done_5 = <0x28>;
			stream_done_6 = <0x29>;
			stream_done_7 = <0x2a>;
			stream_done_8 = <0x2b>;
			stream_done_9 = <0x2c>;
			buf_underrun_event_0 = <0x2d>;
			buf_underrun_event_1 = <0x2e>;
			mdp_tdshp_sof = <0x2f>;
			isp_frame_done_p2_2 = <0x41>;
			isp_frame_done_p2_1 = <0x42>;
			isp_frame_done_p2_0 = <0x43>;
			isp_frame_done_p1_1 = <0x44>;
			isp_frame_done_p1_0 = <0x45>;
			camsv_2_pass1_done = <0x46>;
			camsv_1_pass1_done = <0x47>;
			seninf_cam1_2_3_fifo_full = <0x48>;
			seninf_cam0_fifo_full = <0x49>;
			venc_done = <0x81>;
			jpgenc_done = <0x82>;
			jpgdec_done = <0x83>;
			venc_mb_done = <0x84>;
			venc_128byte_cnt_done = <0x85>;
			apxgpt2_count = <0x10004028>;
			clocks = <0x1e 0x02>;
			clock-names = "GCE";
		};

		cqdma@10217c00 {
			compatible = "mediatek,cqdma";
			reg = <0x10217c00 0xc00>;
			interrupts = <0x00 0x97 0x08>;
			nr_channel = <0x01>;
		};

		mcu_biu@10300000 {
			compatible = "mediatek,mt6735-mcu_biu";
			reg = <0x10300000 0x8000>;
		};

		cpu_dbgapb@10810000 {
			compatible = "mediatek,hw_dbg";
			num = <0x04>;
			reg = <0x10810000 0x1000 0x10910000 0x1000 0x10a10000 0x1000 0x10b10000 0x1000>;
		};

		adc_hw@11001000 {
			compatible = "mediatek,mt6735-auxadc";
			reg = <0x11001000 0x1000>;
			interrupts = <0x00 0x4c 0x02>;
			clocks = <0x02 0x1c>;
			clock-names = "auxadc-main";

			adc_channel@ {
				compatible = "mediatek,adc_channel";
				mediatek,temperature0 = <0x00>;
				mediatek,temperature1 = <0x01>;
				mediatek,adc_fdd_rf_params_dynamic_custom_ch = <0x0c>;
				status = "okay";
			};
		};

		dbgapb_base@1011a000 {
			compatible = "mediatek,dbgapb_base";
			reg = <0x1011a000 0x100>;
		};

		dma@11000000 {
			compatible = "mediatek,ap_dma";
			reg = <0x11000000 0x1000>;
			interrupts = <0x00 0x72 0x08>;
		};

		btif_tx@11000880 {
			compatible = "mediatek,btif_tx";
			reg = <0x11000880 0x80>;
			interrupts = <0x00 0x71 0x08>;
		};

		btif_rx@11000900 {
			compatible = "mediatek,btif_rx";
			reg = <0x11000900 0x80>;
			interrupts = <0x00 0x72 0x08>;
		};

		irtx@11011000 {
			compatible = "mediatek,irtx";
			reg = <0x11011000 0x1000>;
			interrupts = <0x00 0x7c 0x04>;
			pwm_ch = <0x00>;
			clock-frequency = <0x18cba80>;
			clock-div = <0x01>;
			clocks = <0x02 0x1e>;
			clock-names = "clk-irtx-main";
			pinctrl-names = "irtx_gpio_default\0irtx_gpio_led_set";
			pinctrl-0 = <0x24>;
			pinctrl-1 = <0x25>;
			status = "okay";
		};

		irtx-pwm {
			compatible = "mediatek,irtx-pwm";
			pwm_ch = <0x02>;
			pwm_data_invert = <0x00>;
		};

		irlearning-spi {
			compatible = "mediatek,irlearning-spi";
			spi_clock = <0x67f3540>;
			spi_data_invert = <0x00>;
			spi_cs_invert = <0x01>;
		};

		apuart0@11002000 {
			cell-index = <0x00>;
			compatible = "mediatek,mt6735-uart";
			reg = <0x11002000 0x1000 0x11000380 0x1000 0x11000400 0x80>;
			interrupts = <0x00 0x5b 0x08 0x00 0x67 0x08 0x00 0x68 0x08>;
			clock-frequency = <0x18cba80>;
			clock-div = <0x01>;
			clocks = <0x02 0x12 0x02 0x0d>;
			clock-names = "uart0-main\0uart-apdma";
			pinctrl-names = "uart0_gpio_default\0uart0_rx_set\0uart0_rx_clear\0uart0_tx_set\0uart0_tx_clear";
			pinctrl-0 = <0x26>;
			pinctrl-1 = <0x27>;
			pinctrl-2 = <0x28>;
			pinctrl-3 = <0x29>;
			pinctrl-4 = <0x2a>;
			status = "okay";
		};

		apuart1@11003000 {
			cell-index = <0x01>;
			compatible = "mediatek,mt6735-uart";
			reg = <0x11003000 0x1000 0x11000480 0x80 0x11000500 0x80>;
			interrupts = <0x00 0x5c 0x08 0x00 0x69 0x08 0x00 0x6a 0x08>;
			clock-frequency = <0x18cba80>;
			clock-div = <0x01>;
			clocks = <0x02 0x13>;
			clock-names = "uart1-main";
			pinctrl-names = "uart1_gpio_default\0uart1_rx_set\0uart1_rx_clear\0uart1_tx_set\0uart1_tx_clear";
			pinctrl-0 = <0x2b>;
			pinctrl-3 = <0x2c>;
			pinctrl-4 = <0x2d>;
			status = "okay";
		};

		apuart2@11004000 {
			cell-index = <0x02>;
			compatible = "mediatek,mt6735-uart";
			reg = <0x11004000 0x1000 0x11000580 0x80 0x11000600 0x80>;
			interrupts = <0x00 0x5d 0x08 0x00 0x6b 0x08 0x00 0x6c 0x08>;
			clock-frequency = <0x18cba80>;
			clock-div = <0x01>;
			clocks = <0x02 0x14>;
			clock-names = "uart2-main";
			pinctrl-names = "uart2_gpio_default\0uart2_rx_set\0uart2_rx_clear\0uart2_tx_set\0uart2_tx_clear";
			pinctrl-0 = <0x2e>;
			pinctrl-1 = <0x2f>;
			pinctrl-2 = <0x30>;
			pinctrl-3 = <0x31>;
			pinctrl-4 = <0x32>;
			status = "okay";
		};

		apuart3@11005000 {
			cell-index = <0x03>;
			compatible = "mediatek,mt6735-uart";
			reg = <0x11005000 0x1000 0x11000680 0x80 0x11000700 0x80>;
			interrupts = <0x00 0x5e 0x08 0x00 0x6d 0x08 0x00 0x6e 0x08>;
			clock-frequency = <0x18cba80>;
			clock-div = <0x01>;
			clocks = <0x02 0x15>;
			clock-names = "uart3-main";
			pinctrl-names = "uart3_gpio_default\0uart3_rx_set\0uart3_rx_clear\0uart3_tx_set\0uart3_tx_clear";
			pinctrl-0 = <0x33>;
			pinctrl-1 = <0x34>;
			pinctrl-2 = <0x35>;
			pinctrl-3 = <0x36>;
			pinctrl-4 = <0x37>;
			status = "okay";
		};

		pwm@11006000 {
			compatible = "mediatek,pwm";
			reg = <0x11006000 0x1000>;
			interrupts = <0x00 0x4d 0x08>;
			clocks = <0x02 0x0a 0x02 0x03 0x02 0x04 0x02 0x05 0x02 0x06 0x02 0x07>;
			clock-names = "PWM-main\0PWM1-main\0PWM2-main\0PWM3-main\0PWM4-main\0PWM5-main";
		};

		devapc_ao@10007000 {
			compatible = "mediatek,devapc_ao";
			reg = <0x10007000 0x1000>;
		};

		i2c@11007000 {
			compatible = "mediatek,mt6735-i2c";
			cell-index = <0x00>;
			reg = <0x11007000 0x1000>;
			interrupts = <0x00 0x54 0x08 0x00 0x63 0x08>;
			def_speed = <0x64>;
			clocks = <0x02 0x18 0x02 0x0d>;
			clock-names = "i2c0-main\0i2c0-dma";
			clock-frequency = <0x3520>;
			clock-div = <0x01>;
			#address-cells = <0x01>;
			#size-cells = <0x00>;

			camera_main@20 {
				compatible = "mediatek,camera_main";
				reg = <0x20>;
				status = "okay";
			};

			camera_main_af@0c {
				compatible = "mediatek,camera_main_af";
				reg = <0x0c>;
				status = "okay";
			};

			camera_sub@6c {
				compatible = "mediatek,camera_sub";
				reg = <0x6c>;
				status = "okay";
			};
		};

		i2c@11008000 {
			compatible = "mediatek,mt6735-i2c";
			cell-index = <0x01>;
			reg = <0x11008000 0x1000>;
			interrupts = <0x00 0x55 0x08 0x00 0x64 0x08>;
			def_speed = <0x64>;
			clocks = <0x02 0x19 0x02 0x0d>;
			clock-names = "i2c1-main\0i2c1-dma";
			clock-frequency = <0x3520>;
			clock-div = <0x01>;
			#address-cells = <0x01>;
			#size-cells = <0x00>;

			cap_touch@48 {
				compatible = "mediatek,cap_touch";
				reg = <0x48>;
				status = "okay";
			};

			i2c_lcd_bias@3e {
				compatible = "mediatek,i2c_lcd_bias";
				reg = <0x3e>;
				status = "okay";
			};

			swithing_charger@36 {
				compatible = "mediatek,swithing_charger";
				reg = <0x36>;
				status = "okay";
			};

			cap_touch1@20 {
				compatible = "mediatek,cap_touch1";
				reg = <0x20>;
				status = "okay";
			};
		};

		spi@1100a000 {
			compatible = "mediatek,mt6735-spi";
			cell-index = <0x00>;
			spi-padmacro = <0x00>;
			reg = <0x1100a000 0x1000>;
			interrupts = <0x00 0x76 0x08>;
			clocks = <0x02 0x1d>;
			clock-names = "spi-main";
			clock-frequency = <0x67f3540>;
			clock-div = <0x01>;
		};

		i2c@11009000 {
			compatible = "mediatek,mt6735-i2c";
			cell-index = <0x02>;
			reg = <0x11009000 0x1000>;
			interrupts = <0x00 0x56 0x08 0x00 0x65 0x08>;
			def_speed = <0x64>;
			clocks = <0x02 0x1a 0x02 0x0d>;
			clock-names = "i2c2-main\0i2c2-dma";
			clock-frequency = <0x3520>;
			clock-div = <0x01>;
			#address-cells = <0x01>;
			#size-cells = <0x00>;

			MSENSOR@2c {
				compatible = "mediatek,MSENSOR_1";
				reg = <0x2c>;
			};

			GSENSOR@08 {
				compatible = "mediatek,GSENSOR_1";
				reg = <0x08>;
			};

			msensor@30 {
				compatible = "mediatek,msensor";
				reg = <0x30>;
				status = "okay";
			};

			gyro@68 {
				compatible = "mediatek,gyro";
				reg = <0x68>;
				status = "okay";
			};

			gsensor@0e {
				compatible = "mediatek,gsensor";
				reg = <0x0e>;
				status = "okay";
			};

			alsps@49 {
				compatible = "mediatek,alsps";
				reg = <0x49>;
				status = "okay";
			};

			strobe_main@63 {
				compatible = "mediatek,strobe_main";
				reg = <0x63>;
				status = "okay";
			};
		};

		therm_ctrl@1100b000 {
			compatible = "mediatek,mt6735-therm_ctrl";
			reg = <0x1100b000 0x1000>;
			interrupts = <0x00 0x4e 0x08>;
			clocks = <0x02 0x02>;
			clock-names = "therm-main";
		};

		ptp_fsm@1100b000 {
			compatible = "mediatek,ptp_fsm_v1";
			reg = <0x1100b000 0x1000>;
			interrupts = <0x00 0x7d 0x08>;
		};

		btif@1100c000 {
			compatible = "mediatek,btif";
			reg = <0x1100c000 0x1000>;
			interrupts = <0x00 0x5a 0x08>;
			clocks = <0x02 0x17 0x02 0x0d>;
			clock-names = "btifc\0apdmac";
		};

		apuart4@1100D000 {
			cell-index = <0x04>;
			compatible = "mediatek,mt6735-uart";
			reg = <0x1100d000 0x1000 0x11000780 0x80 0x11000800 0x80>;
			interrupts = <0x00 0x5f 0x08 0x00 0x6f 0x08 0x00 0x70 0x08>;
			clock-frequency = <0x18cba80>;
			clock-div = <0x01>;
			clocks = <0x02 0x16>;
			clock-names = "uart4-main";
		};

		i2c@1100f000 {
			compatible = "mediatek,mt6735-i2c";
			cell-index = <0x03>;
			reg = <0x1100f000 0x1000>;
			interrupts = <0x00 0x57 0x08 0x00 0x66 0x08>;
			def_speed = <0x64>;
			clocks = <0x02 0x1b 0x02 0x0d>;
			clock-names = "i2c3-main\0i2c3-dma";
			clock-frequency = <0x3520>;
			clock-div = <0x01>;
			#address-cells = <0x01>;
			#size-cells = <0x00>;

			ext_buck@6b {
				compatible = "mediatek,ext_buck";
				reg = <0x6b>;
				status = "okay";
			};
		};

		i2c@11010000 {
			compatible = "mediatek,mt6735-i2c";
			cell-index = <0x04>;
			reg = <0xa7ffd0 0x1000>;
			def_speed = <0x64>;
			clocks = <0x02 0x1b 0x02 0x0d>;
			clock-names = "i2c4-main\0i2c4-dma";
			clock-frequency = <0x3520>;
			clock-div = <0x01>;
		};

		usb20@11200000 {
			compatible = "mediatek,mt6735-usb20";
			cell-index = <0x00>;
			reg = <0x11200000 0x10000 0x11210000 0x10000>;
			interrupts = <0x00 0x48 0x08>;
			mode = <0x02>;
			multipoint = <0x01>;
			num_eps = <0x10>;
			clocks = <0x02 0x0b>;
			clock-names = "usb0";
			vusb33-supply = <0x38>;
			iddig_gpio = <0x00 0x01>;
			drvvbus_gpio = <0x53 0x02>;
			pinctrl-names = "usb_default\0iddig_irq_init\0drvvbus_init\0drvvbus_low\0drvvbus_high";
			pinctrl-0 = <0x39>;
			pinctrl-1 = <0x3a>;
			pinctrl-2 = <0x3b>;
			pinctrl-3 = <0x3c>;
			pinctrl-4 = <0x3d>;
			status = "okay";
		};

		audiosys@11220000 {
			compatible = "mediatek,mt6735-audiosys";
			reg = <0x11220000 0x10000>;
			#clock-cells = <0x01>;
			linux,phandle = <0x3e>;
			phandle = <0x3e>;
		};

		audio@11220000 {
			compatible = "mediatek,audio";
			reg = <0x11220000 0x10000>;
			interrupts = <0x00 0x90 0x08>;
		};

		mt_soc_dl1_pcm@11220000 {
			compatible = "mediatek,mt-soc-dl1-pcm";
			reg = <0x11220000 0x1000>;
			interrupts = <0x00 0x90 0x08>;
			clocks = <0x3e 0x01 0x3e 0x02 0x3e 0x08 0x3e 0x09 0x3e 0x07 0x3e 0x03 0x3e 0x04 0x3e 0x06 0x3e 0x05 0x3e 0x0a 0x1e 0x06 0x03 0x19 0x03 0x1a 0x03 0x21 0x03 0x4b 0x03 0x11 0x03 0x12 0x03 0x33 0x3f 0x08 0x3f 0x09 0x40>;
			clock-names = "aud_afe_clk\0aud_i2s_clk\0aud_dac_clk\0aud_dac_predis_clk\0aud_adc_clk\0aud_apll22m_clk\0aud_apll24m_clk\0aud_apll1_tuner_clk\0aud_apll2_tuner_clk\0aud_tml_clk\0aud_infra_clk\0aud_mux1_clk\0aud_mux2_clk\0top_ad_apll1_clk\0top_whpll_audio_clk\0top_mux_audio\0top_mux_audio_int\0top_sys_pll1_d4\0apmixed_apll1_clk\0apmixed_apll2_clk\0top_clk26m_clk";
			audclk-gpio = <0x8f 0x00>;
			audmiso-gpio = <0x90 0x00>;
			audmosi-gpio = <0x91 0x00>;
			vowclk-gpio = <0x94 0x00>;
			i2s1clk-gpio = <0x50 0x00>;
			i2s1dat-gpio = <0x4e 0x00>;
			i2s1mclk-gpio = <0x09 0x00>;
			i2s1ws-gpio = <0x4f 0x00>;
			pinctrl-names = "default\0audpmicclk-mode0\0audpmicclk-mode1\0audi2s1-mode0\0audi2s1-mode1\0extamp-pullhigh\0extamp-pulllow\0extamp2-pullhigh\0extamp2-pulllow\0rcvspk-pullhigh\0rcvspk-pulllow";
			pinctrl-0 = <0x41>;
			pinctrl-1 = <0x42>;
			pinctrl-2 = <0x43>;
			pinctrl-3 = <0x44>;
			pinctrl-4 = <0x45>;
			pinctrl-5 = <0x46>;
			pinctrl-6 = <0x47>;
			pinctrl-7 = <0x48>;
			pinctrl-8 = <0x49>;
			pinctrl-9 = <0x4a>;
			pinctrl-10 = <0x4b>;
			status = "okay";
			extspkamp-gpio = <0x78 0x00>;
		};

		mfgsys@13000000 {
			compatible = "mediatek,mt6735-mfgsys";
			reg = <0x13000000 0x1000>;
			#clock-cells = <0x01>;
			linux,phandle = <0x4c>;
			phandle = <0x4c>;
		};

		g3d_config@13000000 {
			compatible = "mediatek,g3d_config";
			reg = <0x13000000 0x1000>;
		};

		mali@13040000 {
			compatible = "arm,malit720\0arm,mali-t72x\0arm,malit7xx\0arm,mali-midgard";
			reg = <0x13040000 0x4000>;
			interrupts = <0x00 0xd4 0x08 0x00 0xd3 0x08 0x00 0xd2 0x08>;
			interrupt-names = "JOB\0MMU\0GPU";
			clock-frequency = <0x1ad27480>;
			clocks = <0x4c 0x01 0x1f 0x01 0x18 0x05 0x18 0x04>;
			clock-names = "mfg-main\0mfg-smi-common\0mtcmos-mfg\0mtcmos-display";
		};

		mmsys@14000000 {
			compatible = "mediatek,mt6735-mmsys";
			reg = <0x14000000 0x1000>;
			#clock-cells = <0x01>;
			linux,phandle = <0x1f>;
			phandle = <0x1f>;
		};

		mmsys_config@14000000 {
			compatible = "mediatek,mmsys_config";
			reg = <0x14000000 0x1000>;
			interrupts = <0x00 0xcd 0x08>;
			clocks = <0x1f 0x03>;
			clock-names = "CAM_MDP";
		};

		mdp_rdma@14001000 {
			compatible = "mediatek,mdp_rdma";
			reg = <0x14001000 0x1000>;
			interrupts = <0x00 0xbb 0x08>;
			clocks = <0x1f 0x04>;
			clock-names = "MDP_RDMA";
		};

		mdp_rsz0@14002000 {
			compatible = "mediatek,mdp_rsz0";
			reg = <0x14002000 0x1000>;
			interrupts = <0x00 0xbc 0x08>;
			clocks = <0x1f 0x05>;
			clock-names = "MDP_RSZ0";
		};

		mdp_rsz1@14003000 {
			compatible = "mediatek,mdp_rsz1";
			reg = <0x14003000 0x1000>;
			interrupts = <0x00 0xbd 0x08>;
			clocks = <0x1f 0x06>;
			clock-names = "MDP_RSZ1";
		};

		mdp_wdma@14004000 {
			compatible = "mediatek,mdp_wdma";
			reg = <0x14004000 0x1000>;
			interrupts = <0x00 0xbf 0x08>;
			clocks = <0x1f 0x08>;
			clock-names = "MDP_WDMA";
		};

		mdp_wrot@14005000 {
			compatible = "mediatek,mdp_wrot";
			reg = <0x14005000 0x1000>;
			interrupts = <0x00 0xc0 0x08>;
			clocks = <0x1f 0x09>;
			clock-names = "MDP_WROT";
		};

		mdp_tdshp@14006000 {
			compatible = "mediatek,mdp_tdshp";
			reg = <0x14006000 0x1000>;
			interrupts = <0x00 0xbe 0x08>;
			clocks = <0x1f 0x07>;
			clock-names = "MDP_TDSHP";
		};

		dpi@14012000 {
			compatible = "mediatek,mt6735-dpi";
			reg = <0x14012000 0x1000>;
			interrupts = <0x00 0xcc 0x08>;
		};

		dispsys@14007000 {
			compatible = "mediatek,mt6735-dispsys";
			reg = <0x14007000 0x1000 0x00 0x00 0x14008000 0x1000 0x14009000 0x1000 0x1400a000 0x1000 0x1400b000 0x1000 0x1400c000 0x1000 0x1400d000 0x1000 0x1400e000 0x1000 0x1400f000 0x1000 0x00 0x00 0x1100e000 0x1000 0x00 0x00 0x14014000 0x1000 0x14011000 0x1000 0x14012000 0x1000 0x14000000 0x1000 0x14015000 0x1000 0x14016000 0x1000 0x14017000 0x1000 0x10206000 0x1000 0x10210000 0x1000 0x10211a70 0x0c 0x10211974 0x0c 0x10211b70 0x0c 0x10206044 0x0c 0x10206514 0x0c 0x10206558 0x0c 0x102100a0 0x1000 0x10209270 0x1000 0x10209274 0x1000 0x00 0x00 0x10209000 0x1000>;
			interrupts = <0x00 0xc1 0x08 0x00 0x00 0x08 0x00 0xc2 0x08 0x00 0xc3 0x08 0x00 0xc4 0x08 0x00 0xc5 0x08 0x00 0xc6 0x08 0x00 0xc7 0x08 0x00 0xc8 0x08 0x00 0xc9 0x08 0x00 0x00 0x08 0x00 0x75 0x08 0x00 0x00 0x08 0x00 0xba 0x08 0x00 0xcb 0x08 0x00 0xcc 0x08 0x00 0xcd 0x08 0x00 0xb0 0x08 0x00 0x00 0x08 0x00 0x00 0x08 0x00 0x00 0x08 0x00 0x00 0x08 0x00 0x00 0x08 0x00 0x00 0x08 0x00 0x00 0x08 0x00 0x00 0x08 0x00 0x00 0x08 0x00 0x00 0x08>;
			clocks = <0x1f 0x01 0x1f 0x02 0x1f 0x0b 0x1f 0x0c 0x1f 0x0d 0x1f 0x0e 0x1f 0x0f 0x1f 0x10 0x1f 0x11 0x1f 0x12 0x1f 0x13 0x1f 0x14 0x1f 0x15 0x1f 0x16 0x1f 0x17 0x02 0x01 0x03 0x16 0x3f 0x07 0x03 0x3c 0x03 0x3d 0x03 0x3e 0x03 0x4d 0x03 0x1d 0x03 0x45 0x03 0x3a 0x03 0x22 0x18 0x04>;
			clock-names = "DISP0_SMI_COMMON\0DISP0_SMI_LARB0\0DISP0_DISP_OVL0\0DISP0_DISP_RDMA0\0DISP0_DISP_RDMA1\0DISP0_DISP_WDMA0\0DISP0_DISP_COLOR\0DISP0_DISP_CCORR\0DISP0_DISP_AAL\0DISP0_DISP_GAMMA\0DISP0_DISP_DITHER\0DISP1_DSI_ENGINE\0DISP1_DSI_DIGITAL\0DISP1_DPI_ENGINE\0DISP1_DPI_PIXEL\0DISP_PWM\0MUX_DPI0\0TVDPLL\0TVDPLL_CK\0TVDPLL_D2\0TVDPLL_D4\0DPI_CK\0MUX_DISPPWM\0UNIVPLL2_D4\0SYSPLL4_D2_D8\0AD_SYS_26M_CK\0DISP_MTCMOS_CLK";
		};

		mhl@0 {
			compatible = "mediatek,extd_dev";
		};

		lcm_mode {
			compatible = "mediatek,lcm_mode";
			pinctrl-names = "default\0lcm_mode_00\0lcm_mode_01\0lcm_mode_02\0lcm_mode_03\0lcm_mode_04\0lcm_mode_05\0lcm_mode_06\0lcm_mode_07";
			pinctrl-0 = <0x4d>;
			pinctrl-1 = <0x4e>;
			pinctrl-2 = <0x4f>;
			pinctrl-3 = <0x50>;
			pinctrl-4 = <0x51>;
			pinctrl-5 = <0x52>;
			pinctrl-6 = <0x53>;
			pinctrl-7 = <0x54>;
			pinctrl-8 = <0x55>;
			lcm_power_gpio = <0x0b 0x50 0x00>;
			lcm_bl_gpio = <0x0b 0x81 0x00>;
			status = "okay";
		};

		smi_larb0@14015000 {
			compatible = "mediatek,smi_larb0";
			reg = <0x14015000 0x1000>;
		};

		smi_common@14016000 {
			compatible = "mediatek,smi_common";
			reg = <0x14016000 0x1000 0x14015000 0x1000 0x16010000 0x1000 0x15001000 0x1000 0x17001000 0x1000>;
			clocks = <0x1f 0x01 0x1f 0x02 0x21 0x01 0x20 0x01 0x20 0x02 0x22 0x01 0x22 0x02 0x18 0x08 0x18 0x07 0x18 0x06 0x18 0x04>;
			clock-names = "smi-common\0smi-larb0\0img-larb2\0vdec0-vdec\0vdec1-larb\0venc-larb\0venc-venc\0mtcmos-ven\0mtcmos-vde\0mtcmos-isp\0mtcmos-dis";
		};

		met_smi@14016000 {
			compatible = "mediatek,met_smi";
			reg = <0x14016000 0x1000 0x14015000 0x1000 0x16010000 0x1000 0x15001000 0x1000 0x17001000 0x1000>;
			clocks = <0x1f 0x01 0x1f 0x02 0x21 0x01 0x20 0x01 0x20 0x02 0x22 0x01 0x22 0x02>;
			clock-names = "smi-common\0smi-larb0\0img-larb2\0vdec0-vdec\0vdec1-larb\0venc-larb\0venc-venc";
		};

		imgsys@15000000 {
			compatible = "mediatek,mt6735-imgsys";
			reg = <0x15000000 0x1000>;
			#clock-cells = <0x01>;
			linux,phandle = <0x21>;
			phandle = <0x21>;
		};

		ispsys@15000000 {
			compatible = "mediatek,mt6735-ispsys";
			reg = <0x15004000 0x9000 0x1500d000 0x1000 0x15000000 0x10000 0x10215000 0x3000 0x10211000 0x1000>;
			interrupts = <0x00 0xb7 0x08 0x00 0xb8 0x08 0x00 0xb9 0x08 0x00 0xce 0x08 0x00 0xcf 0x08>;
			clocks = <0x18 0x04 0x18 0x06 0x1f 0x01 0x21 0x02 0x21 0x03 0x21 0x04 0x21 0x05 0x21 0x06 0x21 0x01>;
			clock-names = "CG_SCP_SYS_DIS\0CG_SCP_SYS_ISP\0CG_DISP0_SMI_COMMON\0CG_IMAGE_CAM_SMI\0CG_IMAGE_CAM_CAM\0CG_IMAGE_SEN_TG\0CG_IMAGE_SEN_CAM\0CG_IMAGE_CAM_SV\0CG_IMAGE_LARB2_SMI";
		};

		smi_larb2@15001000 {
			compatible = "mediatek,smi_larb2";
			reg = <0x15001000 0x1000>;
			interrupts = <0x00 0xb2 0x08>;
		};

		kd_camera_hw1@15008000 {
			compatible = "mediatek,camera_hw";
			reg = <0x15008000 0x1000>;
			vcama-supply = <0x56>;
			vcamd-supply = <0x57>;
			vcamaf-supply = <0x58>;
			vcamio-supply = <0x59>;
			clocks = <0x03 0x08 0x03 0x3f 0x03 0x44>;
			clock-names = "TOP_CAMTG_SEL\0TOP_UNIVPLL_D26\0TOP_UNIVPLL2_D2";
			pinctrl-names = "default\0cam0_rst0\0cam0_rst1\0cam0_pnd0\0cam0_pnd1\0cam1_rst0\0cam1_rst1\0cam1_pnd0\0cam1_pnd1\0cam_ldo0_0\0cam_ldo0_1";
			pinctrl-0 = <0x5a>;
			pinctrl-1 = <0x5b>;
			pinctrl-2 = <0x5c>;
			pinctrl-3 = <0x5d>;
			pinctrl-4 = <0x5e>;
			pinctrl-5 = <0x5f>;
			pinctrl-6 = <0x60>;
			pinctrl-7 = <0x61>;
			pinctrl-8 = <0x62>;
			pinctrl-9 = <0x63>;
			pinctrl-10 = <0x64>;
			status = "okay";
			vcama_main2-supply = <0x56>;
			vcama_sub-supply = <0x56>;
			vcamaf_main2-supply = <0x58>;
			vcamaf_sub-supply = <0x58>;
			vcamd_main2-supply = <0x57>;
			vcamd_sub-supply = <0x57>;
			vcamio_main2-supply = <0x59>;
			vcamio_sub-supply = <0x59>;
		};

		kd_camera_hw2@15008000 {
			compatible = "mediatek,camera_hw2";
			reg = <0x15008000 0x1000>;
		};

		fdvt@1500b000 {
			compatible = "mediatek,fdvt";
			reg = <0x1500b000 0x1000>;
			interrupts = <0x00 0xd0 0x08>;
			clocks = <0x18 0x04 0x18 0x06 0x1f 0x01 0x21 0x08>;
			clock-names = "FD-SCP_SYS_DIS\0FD-SCP_SYS_ISP\0FD-MM_DISP0_SMI_COMMON\0FD-IMG_IMAGE_FD";
		};

		vdecsys@16000000 {
			compatible = "mediatek,mt6735-vdecsys";
			reg = <0x16000000 0x1000>;
			interrupts = <0x00 0xb3 0x08>;
			#clock-cells = <0x01>;
			linux,phandle = <0x20>;
			phandle = <0x20>;
		};

		c2k_sdio@0 {
			compatible = "mediatek,mt6735-c2k_sdio";
			interrupts = <0x00 0xe6 0x08>;
		};

		vdec_gcon@16000000 {
			compatible = "mediatek,mt6735-vdec_gcon";
			reg = <0x16000000 0x1000>;
			interrupts = <0x00 0xb3 0x08>;
			clocks = <0x1f 0x01 0x20 0x01 0x20 0x02 0x22 0x02 0x22 0x01 0x03 0x06 0x03 0x32 0x03 0x33 0x18 0x07 0x18 0x08 0x18 0x04>;
			clock-names = "MT_CG_DISP0_SMI_COMMON\0MT_CG_VDEC0_VDEC\0MT_CG_VDEC1_LARB\0MT_CG_VENC_VENC\0MT_CG_VENC_LARB\0MT_CG_TOP_MUX_VDEC\0MT_CG_TOP_SYSPLL1_D2\0MT_CG_TOP_SYSPLL1_D4\0MT_SCP_SYS_VDE\0MT_SCP_SYS_VEN\0MT_SCP_SYS_DIS";
		};

		smi_larb1@16010000 {
			compatible = "mediatek,smi_larb1";
			reg = <0x16010000 0x1000>;
			interrupts = <0x00 0xb1 0x08>;
		};

		vdec@16020000 {
			compatible = "mediatek,mt6735-vdec";
			reg = <0x16020000 0x10000>;
			interrupts = <0x00 0xb3 0x08>;
		};

		vencsys@17000000 {
			compatible = "mediatek,mt6735-vencsys";
			reg = <0x17000000 0x1000>;
			interrupts = <0x00 0xb4 0x08>;
			#clock-cells = <0x01>;
			linux,phandle = <0x22>;
			phandle = <0x22>;
		};

		venc_gcon@17000000 {
			compatible = "mediatek,mt6735-venc_gcon";
			reg = <0x17000000 0x1000>;
			interrupts = <0x00 0xb4 0x08>;
		};

		smi_larb3@17001000 {
			compatible = "mediatek,smi_larb3";
			reg = <0x17001000 0x1000>;
			interrupts = <0x00 0xca 0x08>;
		};

		venc@17002000 {
			compatible = "mediatek,mt6735-venc";
			reg = <0x17002000 0x1000>;
			interrupts = <0x00 0xb4 0x08>;
		};

		jpgenc@17003000 {
			compatible = "mediatek,jpgenc";
			reg = <0x17003000 0x1000>;
			interrupts = <0x00 0xb5 0x08>;
			clocks = <0x18 0x04 0x1f 0x01 0x18 0x08 0x22 0x01 0x22 0x03>;
			clock-names = "disp-mtcmos\0disp-smi\0venc-mtcmos\0venc-larb\0venc-jpgenc";
		};

		jpgdec@17004000 {
			compatible = "mediatek,jpgdec";
			reg = <0x17004000 0x1000>;
			interrupts = <0x00 0xd1 0x08>;
			clocks = <0x18 0x04 0x1f 0x01 0x18 0x08 0x22 0x01 0x22 0x04>;
			clock-names = "disp-mtcmos\0disp-smi\0venc-mtcmos\0venc-larb\0venc-jpgdec";
		};

		consys@18070000 {
			compatible = "mediatek,mt6735-consys";
			reg = <0x18070000 0x200 0x10212000 0x100 0x10000000 0x2000 0x10006000 0x1000>;
			interrupts = <0x00 0xe3 0x08 0x00 0xe1 0x08>;
			clocks = <0x18 0x03 0x1e 0x0b>;
			clock-names = "conn\0bus";
			vcn18-supply = <0x65>;
			vcn28-supply = <0x66>;
			vcn33_bt-supply = <0x67>;
			vcn33_wifi-supply = <0x68>;
			pinctrl-names = "default\0gps_lna_state_init\0gps_lna_state_oh\0gps_lna_state_ol";
			pinctrl-0 = <0x0d>;
			pinctrl-1 = <0x69>;
			pinctrl-2 = <0x6a>;
			pinctrl-3 = <0x6b>;
			status = "okay";
		};

		wifi@180F0000 {
			compatible = "mediatek,wifi";
			reg = <0x180f0000 0x5c>;
			interrupts = <0x00 0xe2 0x08>;
			clocks = <0x02 0x0d>;
			clock-names = "wifi-dma";
		};

		mdc2k@3a00b01c {
			compatible = "mediatek,mdc2k";
			reg = <0x3a00b01c 0x10 0x1021c800 0x300 0x1021d800 0x300>;
			interrupts = <0x00 0xe5 0x02>;
			clocks = <0x18 0x02>;
			clock-names = "scp-sys-md2-main";
		};

		mtkfb@7e000000 {
			compatible = "mediatek,mtkfb";
			reg = <0x7e000000 0x1000000>;
		};

		mt_soc_ul1_pcm {
			compatible = "mediatek,mt_soc_pcm_capture";
		};

		mt_soc_voice_md1 {
			compatible = "mediatek,mt_soc_pcm_voice_md1";
		};

		mt_soc_hdmi_pcm {
			compatible = "mediatek,mt_soc_pcm_hdmi";
		};

		mt_soc_uldlloopback_pcm {
			compatible = "mediatek,mt_soc_pcm_uldlloopback";
		};

		mt_soc_i2s0_pcm {
			compatible = "mediatek,mt_soc_pcm_dl1_i2s0";
		};

		mt_soc_mrgrx_pcm {
			compatible = "mediatek,mt_soc_pcm_mrgrx";
		};

		mt_soc_mrgrx_awb_pcm {
			compatible = "mediatek,mt_soc_pcm_mrgrx_awb";
		};

		mt_soc_fm_i2s_pcm {
			compatible = "mediatek,mt_soc_pcm_fm_i2s";
		};

		mt_soc_fm_i2s_awb_pcm {
			compatible = "mediatek,mt_soc_pcm_fm_i2s_awb";
		};

		mt_soc_i2s0dl1_pcm {
			compatible = "mediatek,mt_soc_pcm_dl1_i2s0Dl1";
		};

		mt_soc_dl1_awb_pcm {
			compatible = "mediatek,mt_soc_pcm_dl1_awb";
		};

		mt_soc_voice_md1_bt {
			compatible = "mediatek,mt_soc_pcm_voice_md1_bt";
		};

		mt_soc_voip_bt_out {
			compatible = "mediatek,mt_soc_pcm_dl1_bt";
		};

		mt_soc_voip_bt_in {
			compatible = "mediatek,mt_soc_pcm_bt_dai";
		};

		mt_soc_tdmrx_pcm {
			compatible = "mediatek,mt_soc_tdm_capture";
		};

		mt_soc_fm_mrgtx_pcm {
			compatible = "mediatek,mt_soc_pcm_fmtx";
		};

		mt_soc_ul2_pcm {
			compatible = "mediatek,mt_soc_pcm_capture2";
		};

		mt_soc_i2s0_awb_pcm {
			compatible = "mediatek,mt_soc_pcm_i2s0_awb";
		};

		mt_soc_voice_md2 {
			compatible = "mediatek,mt_soc_pcm_voice_md2";
		};

		mt_soc_routing_pcm {
			compatible = "mediatek,mt_soc_pcm_routing";
			i2s1clk-gpio = <0x07 0x06>;
			i2s1dat-gpio = <0x05 0x06>;
			i2s1mclk-gpio = <0x09 0x06>;
			i2s1ws-gpio = <0x06 0x06>;
		};

		mt_soc_voice_md2_bt {
			compatible = "mediatek,mt_soc_pcm_voice_md2_bt";
		};

		mt_soc_hp_impedance_pcm {
			compatible = "mediatek,Mt_soc_pcm_hp_impedance";
		};

		mt_soc_codec_name {
			compatible = "mediatek,mt_soc_codec_63xx";
		};

		mt_soc_dummy_pcm {
			compatible = "mediatek,mt_soc_pcm_dummy";
		};

		mt_soc_codec_dummy_name {
			compatible = "mediatek,mt_soc_codec_dummy";
		};

		mt_soc_routing_dai_name {
			compatible = "mediatek,mt_soc_dai_routing";
		};

		mt_soc_dai_name {
			compatible = "mediatek,mt_soc_dai_stub";
		};

		mt_soc_offload_gdma {
			compatible = "mediatek,mt_soc_pcm_offload_gdma";
		};

		mt_soc_dl2_pcm {
			compatible = "mediatek,mt_soc_pcm_dl2";
		};

		touch {
			compatible = "mediatek,mt6735-touch";
			vtouch-supply = <0x6c>;
			tpd-resolution = <0x2d0 0x500>;
			use-tpd-button = <0x00>;
			tpd-key-num = <0x03>;
			tpd-key-local = <0x8b 0xac 0x9e 0x00>;
			tpd-key-dim-local = <0x5a 0x373 0x64 0x28 0xe6 0x373 0x64 0x28 0x172 0x373 0x64 0x28 0x00 0x00 0x00 0x00>;
			tpd-max-touch-num = <0x05>;
			tpd-filter-enable = <0x01>;
			tpd-filter-pixel-density = <0x7c>;
			tpd-filter-custom-prameters = <0x00 0x00 0x00 0x00 0x00 0x00 0x00 0x00 0x00 0x00 0x00 0x00>;
			tpd-filter-custom-speed = <0x00 0x00 0x00>;
			pinctrl-names = "default\0state_eint_as_int\0state_eint_output0\0state_eint_output1\0state_rst_output0\0state_rst_output1";
			pinctrl-0 = <0x6d>;
			pinctrl-1 = <0x6e>;
			pinctrl-2 = <0x6f>;
			pinctrl-3 = <0x70>;
			pinctrl-4 = <0x71>;
			pinctrl-5 = <0x72>;
			status = "okay";
			interrupt-parent = <0x0c>;
			interrupts = <0x0a 0x02>;
			debounce = <0x0a 0x00>;
		};

		hall_1 {
			compatible = "mediatek,hall-eint";
			interrupt-parent = <0x0c>;
			interrupts = <0x02 0x02>;
			debounce = <0x02 0x00>;
			status = "okay";
		};

		accdet {
			compatible = "mediatek,mt6735-accdet";
			accdet-mic-vol = <0x07>;
			headset-mode-setting = <0x500 0x200 0x01 0x1f0 0x800 0x800 0x20>;
			accdet-plugout-debounce = <0x14>;
			accdet-mic-mode = <0x01>;
			headset-three-key-threshold = <0x00 0x50 0xdc 0x1f4>;
			headset-four-key-threshold = <0x00 0x3a 0x79 0xc0 0x1c2>;
			pinctrl-names = "default\0state_eint_as_int";
			pinctrl-0 = <0x73>;
			pinctrl-1 = <0x74>;
			status = "okay";
			interrupt-parent = <0x0c>;
			interrupts = <0x06 0x08>;
			debounce = <0x06 0x3e800>;
		};

		nfc {
			compatible = "mediatek,nfc-gpio-v2";
			gpio-ven = <0x04>;
			gpio-rst = <0x03>;
			gpio-eint = <0x01>;
			gpio-irq = <0x02>;
			pinctrl-names = "default\0ven_high\0ven_low\0rst_high\0rst_low\0eint_high\0eint_low\0irq_init";
			pinctrl-0 = <0x0d>;
			pinctrl-1 = <0x75>;
			pinctrl-2 = <0x76>;
			pinctrl-3 = <0x77>;
			pinctrl-4 = <0x78>;
			pinctrl-5 = <0x79>;
			pinctrl-6 = <0x7a>;
			pinctrl-7 = <0x7b>;
			status = "okay";
		};

		gps {
			compatible = "mediatek,gps";
		};

		simswitch {
			compatible = "mediatek,sim_switch";
			pinctrl-names = "default\0hot_plug_mode1\0hot_plug_mode2\0two_sims_bound_to_md1\0sim1_md3_sim2_md1";
			pinctrl-0 = <0x7c>;
			pinctrl-1 = <0x7d>;
			pinctrl-2 = <0x7e>;
			pinctrl-3 = <0x7f>;
			pinctrl-4 = <0x80>;
		};

		ccci_off {
			compatible = "mediatek,ccci_off";
			clocks = <0x18 0x01>;
			clock-names = "scp-sys-md1-main";
		};

		pmu {
			compatible = "arm,armv8-pmuv3";
			interrupts = <0x00 0x08 0x08 0x00 0x09 0x08 0x00 0x0a 0x08 0x00 0x0b 0x08>;
			interrupt-affinity = <0x14 0x15 0x16 0x17>;
		};

		timer {
			compatible = "arm,armv8-timer";
			interrupts = <0x01 0x0d 0x08 0x01 0x0e 0x08 0x01 0x0b 0x08 0x01 0x0a 0x08>;
			clock-frequency = <0xc65d40>;
		};

		mt_pmic_regulator {
			compatible = "mediatek,mt_pmic";

			buck_regulators {
				compatible = "mediatek,mt_pmic_buck_regulators";

				buck_vpa {
					regulator-name = "vpa";
					regulator-min-microvolt = <0x7a120>;
					regulator-max-microvolt = <0x37b1d0>;
					regulator-ramp-delay = <0xc350>;
					regulator-enable-ramp-delay = <0xb4>;
				};

				buck_vproc {
					regulator-name = "vproc";
					regulator-min-microvolt = <0x927c0>;
					regulator-max-microvolt = <0x154456>;
					regulator-ramp-delay = <0x186a>;
					regulator-enable-ramp-delay = <0xb4>;
					regulator-always-on;
					regulator-boot-on;
				};

				buck_vcore1 {
					regulator-name = "vcore1";
					regulator-min-microvolt = <0x927c0>;
					regulator-max-microvolt = <0x154456>;
					regulator-ramp-delay = <0x186a>;
					regulator-enable-ramp-delay = <0xb4>;
					regulator-always-on;
					regulator-boot-on;
				};

				buck_vsys22 {
					regulator-name = "vsys22";
					regulator-min-microvolt = <0x124f80>;
					regulator-max-microvolt = <0x1e6c16>;
					regulator-ramp-delay = <0x186a>;
					regulator-enable-ramp-delay = <0xb4>;
					regulator-always-on;
					regulator-boot-on;
				};

				buck_vlte {
					regulator-name = "vlte";
					regulator-min-microvolt = <0x927c0>;
					regulator-max-microvolt = <0x154456>;
					regulator-ramp-delay = <0x186a>;
					regulator-enable-ramp-delay = <0xb4>;
					regulator-always-on;
					regulator-boot-on;
				};
			};

			ldo_regulators {
				compatible = "mediatek,mt_pmic_ldo_regulators";

				ldo_vaux18 {
					regulator-name = "vaux18";
					regulator-min-microvolt = <0x1b7740>;
					regulator-max-microvolt = <0x1b7740>;
					regulator-enable-ramp-delay = <0x108>;
					regulator-boot-on;
					linux,phandle = <0x81>;
					phandle = <0x81>;
				};

				ldo_vtcxo_0 {
					regulator-name = "vtcxo_0";
					regulator-min-microvolt = <0x2ab980>;
					regulator-max-microvolt = <0x2ab980>;
					regulator-enable-ramp-delay = <0x6e>;
					regulator-boot-on;
					linux,phandle = <0x82>;
					phandle = <0x82>;
				};

				ldo_vtcxo_1 {
					regulator-name = "vtcxo_1";
					regulator-min-microvolt = <0x2ab980>;
					regulator-max-microvolt = <0x2ab980>;
					regulator-enable-ramp-delay = <0x6e>;
					linux,phandle = <0x83>;
					phandle = <0x83>;
				};

				ldo_vaud28 {
					regulator-name = "vaud28";
					regulator-min-microvolt = <0x2ab980>;
					regulator-max-microvolt = <0x2ab980>;
					regulator-enable-ramp-delay = <0x108>;
					regulator-boot-on;
					linux,phandle = <0x84>;
					phandle = <0x84>;
				};

				ldo_vcn28 {
					regulator-name = "vcn28";
					regulator-min-microvolt = <0x2ab980>;
					regulator-max-microvolt = <0x2ab980>;
					regulator-enable-ramp-delay = <0x108>;
					linux,phandle = <0x66>;
					phandle = <0x66>;
				};

				ldo_vcama {
					regulator-name = "vcama";
					regulator-min-microvolt = <0x16e360>;
					regulator-max-microvolt = <0x2ab980>;
					regulator-enable-ramp-delay = <0x108>;
					regulator-default-on = <0x00>;
					status = "okay";
					linux,phandle = <0x56>;
					phandle = <0x56>;
				};

				ldo_vcn33_bt {
					regulator-name = "vcn33_bt";
					regulator-min-microvolt = <0x325aa0>;
					regulator-max-microvolt = <0x36ee80>;
					regulator-enable-ramp-delay = <0x108>;
					linux,phandle = <0x67>;
					phandle = <0x67>;
				};

				ldo_vcn33_wifi {
					regulator-name = "vcn33_wifi";
					regulator-min-microvolt = <0x325aa0>;
					regulator-max-microvolt = <0x36ee80>;
					regulator-enable-ramp-delay = <0x108>;
					linux,phandle = <0x68>;
					phandle = <0x68>;
				};

				ldo_vusb33 {
					regulator-name = "vusb33";
					regulator-min-microvolt = <0x325aa0>;
					regulator-max-microvolt = <0x325aa0>;
					regulator-enable-ramp-delay = <0x108>;
					regulator-boot-on;
					linux,phandle = <0x38>;
					phandle = <0x38>;
				};

				ldo_vefuse {
					regulator-name = "vefuse";
					regulator-min-microvolt = <0x1b7740>;
					regulator-max-microvolt = <0x2191c0>;
					regulator-enable-ramp-delay = <0x108>;
					linux,phandle = <0x85>;
					phandle = <0x85>;
				};

				ldo_vsim1 {
					regulator-name = "vsim1";
					regulator-min-microvolt = <0x19f0a0>;
					regulator-max-microvolt = <0x200b20>;
					regulator-enable-ramp-delay = <0x108>;
					regulator-default-on = <0x00>;
					status = "okay";
					linux,phandle = <0x86>;
					phandle = <0x86>;
				};

				ldo_vsim2 {
					regulator-name = "vsim2";
					regulator-min-microvolt = <0x19f0a0>;
					regulator-max-microvolt = <0x200b20>;
					regulator-enable-ramp-delay = <0x108>;
					regulator-default-on = <0x00>;
					status = "okay";
					linux,phandle = <0x87>;
					phandle = <0x87>;
				};

				ldo_vemc_3v3 {
					regulator-name = "vemc_3v3";
					regulator-min-microvolt = <0x1b7740>;
					regulator-max-microvolt = <0x325aa0>;
					regulator-enable-ramp-delay = <0x108>;
					regulator-boot-on;
					linux,phandle = <0x88>;
					phandle = <0x88>;
				};

				ldo_vmch {
					regulator-name = "vmch";
					regulator-min-microvolt = <0x2c4020>;
					regulator-max-microvolt = <0x325aa0>;
					regulator-enable-ramp-delay = <0x2c>;
					linux,phandle = <0x89>;
					phandle = <0x89>;
				};

				ldo_vtref {
					regulator-name = "vtref";
					regulator-min-microvolt = <0x1b7740>;
					regulator-max-microvolt = <0x1b7740>;
					regulator-enable-ramp-delay = <0xf0>;
					linux,phandle = <0x8a>;
					phandle = <0x8a>;
				};

				ldo_vmc {
					regulator-name = "vmc";
					regulator-min-microvolt = <0x1b7740>;
					regulator-max-microvolt = <0x325aa0>;
					regulator-enable-ramp-delay = <0x2c>;
					linux,phandle = <0x8b>;
					phandle = <0x8b>;
				};

				ldo_vcamaf {
					regulator-name = "vcamaf";
					regulator-min-microvolt = <0x124f80>;
					regulator-max-microvolt = <0x325aa0>;
					regulator-enable-ramp-delay = <0x108>;
					regulator-default-on = <0x00>;
					status = "okay";
					linux,phandle = <0x58>;
					phandle = <0x58>;
				};

				ldo_vio28 {
					regulator-name = "vio28";
					regulator-min-microvolt = <0x2ab980>;
					regulator-max-microvolt = <0x2ab980>;
					regulator-enable-ramp-delay = <0x108>;
					regulator-boot-on;
					linux,phandle = <0x8c>;
					phandle = <0x8c>;
				};

				ldo_vgp1 {
					regulator-name = "vgp1";
					regulator-min-microvolt = <0x124f80>;
					regulator-max-microvolt = <0x325aa0>;
					regulator-enable-ramp-delay = <0x108>;
					regulator-default-on = <0x00>;
					status = "okay";
					linux,phandle = <0x6c>;
					phandle = <0x6c>;
				};

				ldo_vibr {
					regulator-name = "vibr";
					regulator-min-microvolt = <0x124f80>;
					regulator-max-microvolt = <0x325aa0>;
					regulator-enable-ramp-delay = <0x2c>;
					regulator-default-on = <0x00>;
					status = "okay";
					linux,phandle = <0x8d>;
					phandle = <0x8d>;
				};

				ldo_vcamd {
					regulator-name = "vcamd";
					regulator-min-microvolt = <0xdbba0>;
					regulator-max-microvolt = <0x16e360>;
					regulator-enable-ramp-delay = <0x108>;
					regulator-default-on = <0x00>;
					status = "okay";
					linux,phandle = <0x57>;
					phandle = <0x57>;
				};

				ldo_vrf18_0 {
					regulator-name = "vrf18_0";
					regulator-min-microvolt = <0x1bd8e8>;
					regulator-max-microvolt = <0x1bd8e8>;
					regulator-enable-ramp-delay = <0xdc>;
					linux,phandle = <0x8e>;
					phandle = <0x8e>;
				};

				ldo_vrf18_1 {
					regulator-name = "vrf18_1";
					regulator-min-microvolt = <0x124f80>;
					regulator-max-microvolt = <0x1bd8e8>;
					regulator-enable-ramp-delay = <0xdc>;
					linux,phandle = <0x8f>;
					phandle = <0x8f>;
				};

				ldo_vio18 {
					regulator-name = "vio18";
					regulator-min-microvolt = <0x1b7740>;
					regulator-max-microvolt = <0x1b7740>;
					regulator-enable-ramp-delay = <0x108>;
					regulator-boot-on;
					linux,phandle = <0x90>;
					phandle = <0x90>;
				};

				ldo_vcn18 {
					regulator-name = "vcn18";
					regulator-min-microvolt = <0x1b7740>;
					regulator-max-microvolt = <0x1b7740>;
					regulator-enable-ramp-delay = <0x2c>;
					linux,phandle = <0x65>;
					phandle = <0x65>;
				};

				ldo_vcamio {
					regulator-name = "vcamio";
					regulator-min-microvolt = <0x124f80>;
					regulator-max-microvolt = <0x1b7740>;
					regulator-enable-ramp-delay = <0xdc>;
					regulator-default-on = <0x00>;
					status = "okay";
					linux,phandle = <0x59>;
					phandle = <0x59>;
				};

				ldo_vsram {
					regulator-name = "vsram";
					regulator-min-microvolt = <0xaae60>;
					regulator-max-microvolt = <0x16caf6>;
					regulator-enable-ramp-delay = <0xdc>;
					regulator-ramp-delay = <0x186a>;
					regulator-boot-on;
					linux,phandle = <0x91>;
					phandle = <0x91>;
				};

				ldo_vm {
					regulator-name = "vm";
					regulator-min-microvolt = <0x12ebc0>;
					regulator-max-microvolt = <0x177fa0>;
					regulator-enable-ramp-delay = <0x108>;
					regulator-boot-on;
					linux,phandle = <0x92>;
					phandle = <0x92>;
				};
			};

			regulators_supply {
				compatible = "mediatek,mt_pmic_regulator_supply";
				vaux18-supply = <0x81>;
				vtcxo_0-supply = <0x82>;
				vtcxo_1-supply = <0x83>;
				vaud28-supply = <0x84>;
				vefuse-supply = <0x85>;
				vsim1-supply = <0x86>;
				vsim2-supply = <0x87>;
				vemc_3v3-supply = <0x88>;
				vmch-supply = <0x89>;
				vtref-supply = <0x8a>;
				vmc-supply = <0x8b>;
				vio28-supply = <0x8c>;
				vibr-supply = <0x8d>;
				vrf18_0-supply = <0x8e>;
				vrf18_1-supply = <0x8f>;
				vio18-supply = <0x90>;
				vsram-supply = <0x91>;
				vm-supply = <0x92>;
			};
		};

		btcvsd@10000000 {
			compatible = "mediatek,audio_bt_cvsd";
			offset = <0x700 0x800 0xfd0 0xfd4 0xfd8>;
			reg = <0x10000000 0x1000 0x18000000 0x10000 0x18080000 0x8000>;
			interrupts = <0x00 0xe4 0x08>;
		};

		bat_meter {
			compatible = "mediatek,bat_meter";
			r_bat_sense = <0x04>;
			r_i_sense = <0x04>;
			r_charger_1 = <0x14a>;
			r_charger_2 = <0x27>;
			temperature_t0 = <0x6e>;
			temperature_t1 = <0x00>;
			temperature_t2 = <0x19>;
			temperature_t3 = <0x32>;
			temperature_t = <0xff>;
			fg_meter_resistance = <0x00>;
			q_max_pos_50 = <0xf33>;
			q_max_pos_25 = <0xeba>;
			q_max_pos_0 = <0xe0a>;
			q_max_neg_10 = <0xd17>;
			q_max_pos_50_h_current = <0xefe>;
			q_max_pos_25_h_current = <0xea0>;
			q_max_pos_0_h_current = <0xd7c>;
			q_max_neg_10_h_current = <0x764>;
			oam_d5 = <0x01>;
			change_tracking_point = <0x01>;
			cust_tracking_point = <0x01>;
			cust_r_sense = <0x21>;
			cust_hw_cc = <0x00>;
			aging_tuning_value = <0x67>;
			cust_r_fg_offset = <0x00>;
			ocv_board_compesate = <0x00>;
			r_fg_board_base = <0x3e8>;
			r_fg_board_slope = <0x3e8>;
			car_tune_value = <0x4d>;
			current_detect_r_fg = <0x0a>;
			minerroroffset = <0x3e8>;
			fg_vbat_average_size = <0x12>;
			r_fg_value = <0x0a>;
			cust_poweron_delta_capacity_tolrance = <0x28>;
			cust_poweron_low_capacity_tolrance = <0x05>;
			cust_poweron_max_vbat_tolrance = <0x5a>;
			cust_poweron_delta_vbat_tolrance = <0x1e>;
			cust_poweron_delta_hw_sw_ocv_capacity_tolrance = <0x0a>;
			fixed_tbat_25 = <0x00>;
			vbat_normal_wakeup = <0xe10>;
			vbat_low_power_wakeup = <0xdac>;
			normal_wakeup_period = <0x1518>;
			low_power_wakeup_period = <0x12c>;
			close_poweroff_wakeup_period = <0x1e>;
			rbat_pull_up_r = <0xf1cc>;
			rbat_pull_up_volt = <0x708>;
			batt_temperature_table_num = <0x11>;
			batt_temperature_table = <0xffffffec 0x5ec3a 0xfffffff1 0x58192 0xfffffff6 0x42551 0xfffffffb 0x3267f 0x00 0x26a06 0x05 0x1dd93 0x0a 0x173fb 0x0f 0x123ea 0x14 0xe6b9 0x19 0xb798 0x1e 0x930b 0x23 0x767e 0x28 0x600f 0x2d 0x4e50 0x32 0x4031 0x37 0x34e3 0x3c 0x2bca>;
			battery_profile_t0_num = <0x56>;
			battery_profile_t0 = <0x00 0x1128 0x01 0x1114 0x03 0x10ff 0x04 0x10ed 0x06 0x10da 0x07 0x10c8 0x09 0x10b6 0x0a 0x10a5 0x0c 0x1091 0x0d 0x107a 0x0f 0x105d 0x10 0x103f 0x12 0x1023 0x13 0x1011 0x15 0x1003 0x16 0xff6 0x18 0xfe8 0x19 0xfd7 0x1b 0xfc4 0x1c 0xfb1 0x1e 0xf9f 0x1f 0xf90 0x21 0xf82 0x22 0xf75 0x24 0xf68 0x25 0xf5d 0x27 0xf51 0x28 0xf46 0x2a 0xf3b 0x2b 0xf31 0x2d 0xf28 0x2e 0xf1f 0x30 0xf17 0x31 0xf10 0x33 0xf09 0x34 0xf02 0x36 0xefc 0x37 0xef6 0x39 0xef0 0x3a 0xeeb 0x3c 0xee6 0x3d 0xee2 0x3f 0xede 0x40 0xeda 0x42 0xed7 0x43 0xed3 0x45 0xed0 0x46 0xecd 0x48 0xec9 0x49 0xec5 0x4b 0xec1 0x4c 0xebd 0x4e 0xeb8 0x4f 0xeb3 0x51 0xead 0x52 0xea7 0x54 0xea1 0x55 0xe99 0x56 0xe91 0x57 0xe8a 0x58 0xe85 0x59 0xe81 0x5a 0xe7e 0x5b 0xe79 0x5c 0xe75 0x5d 0xe73 0x5e 0xe71 0x5f 0xe6e 0x60 0xe6a 0x61 0xe64 0x62 0xe5d 0x63 0xe4c 0x64 0xd48 0x64 0xd48 0x64 0xd48 0x64 0xd48 0x64 0xd48 0x64 0xd48 0x64 0xd48 0x64 0xd48 0x64 0xd48 0x64 0xd48 0x64 0xd48 0x64 0xd48 0x64 0xd48 0x64 0xd48>;
			battery_profile_t1_num = <0x56>;
			battery_profile_t1 = <0x00 0x1129 0x01 0x1118 0x03 0x1103 0x04 0x10f2 0x06 0x10e2 0x07 0x10d3 0x08 0x10c4 0x0a 0x10b5 0x0b 0x10a7 0x0d 0x1099 0x0e 0x108b 0x0f 0x107c 0x11 0x106e 0x12 0x1060 0x13 0x1052 0x15 0x1045 0x16 0x1037 0x18 0x102a 0x19 0x101c 0x1a 0x100e 0x1c 0x1000 0x1d 0xff4 0x1f 0xfe7 0x20 0xfda 0x21 0xfc8 0x23 0xfb3 0x24 0xf9d 0x26 0xf89 0x27 0xf78 0x28 0xf6b 0x2a 0xf60 0x2b 0xf58 0x2d 0xf4f 0x2e 0xf47 0x2f 0xf3f 0x31 0xf37 0x32 0xf2f 0x33 0xf27 0x35 0xf20 0x36 0xf18 0x38 0xf12 0x39 0xf0b 0x3a 0xf04 0x3c 0xefe 0x3d 0xef8 0x3f 0xef2 0x40 0xeec 0x41 0xee6 0x43 0xee1 0x44 0xedb 0x46 0xed6 0x47 0xed0 0x48 0xecb 0x4a 0xec6 0x4b 0xec0 0x4d 0xebb 0x4e 0xeb6 0x4f 0xeb0 0x51 0xea9 0x52 0xea3 0x53 0xe9b 0x55 0xe93 0x56 0xe8b 0x58 0xe81 0x59 0xe7b 0x5a 0xe77 0x5c 0xe74 0x5d 0xe72 0x5f 0xe6e 0x60 0xe65 0x61 0xe46 0x63 0xe0b 0x64 0xd48 0x64 0xd48 0x64 0xd48 0x64 0xd48 0x64 0xd48 0x64 0xd48 0x64 0xd48 0x64 0xd48 0x64 0xd48 0x64 0xd48 0x64 0xd48 0x64 0xd48 0x64 0xd48 0x64 0xd48>;
			battery_profile_t2_num = <0x56>;
			battery_profile_t2 = <0x00 0x110d 0x01 0x110c 0x02 0x10fd 0x04 0x10ee 0x05 0x10e0 0x06 0x10d1 0x07 0x10c3 0x09 0x10b4 0x0a 0x10a6 0x0b 0x1097 0x0c 0x108a 0x0d 0x107c 0x0f 0x106d 0x10 0x105e 0x11 0x1052 0x12 0x1044 0x14 0x1035 0x15 0x1026 0x16 0x101a 0x17 0x100c 0x18 0xfff 0x1a 0xff2 0x1b 0xfe5 0x1c 0xfdc 0x1d 0xfcf 0x1e 0xfc3 0x20 0xfb7 0x21 0xfaa 0x22 0xf9f 0x23 0xf94 0x25 0xf8a 0x26 0xf82 0x27 0xf79 0x28 0xf6f 0x29 0xf63 0x2b 0xf57 0x2c 0xf48 0x2d 0xf38 0x2e 0xf2b 0x30 0xf21 0x31 0xf19 0x32 0xf12 0x33 0xf0a 0x34 0xf04 0x36 0xefd 0x37 0xef9 0x38 0xef3 0x39 0xeee 0x3b 0xee9 0x3c 0xee5 0x3d 0xede 0x3e 0xedb 0x3f 0xed7 0x41 0xed4 0x42 0xed1 0x43 0xece 0x44 0xecb 0x45 0xec8 0x47 0xec5 0x48 0xec1 0x49 0xebc 0x4a 0xeb6 0x4c 0xeb1 0x4d 0xead 0x4e 0xea9 0x4f 0xea3 0x50 0xea0 0x52 0xe9c 0x53 0xe97 0x54 0xe8f 0x55 0xe86 0x57 0xe80 0x58 0xe78 0x59 0xe6e 0x5a 0xe6b 0x5b 0xe69 0x5d 0xe68 0x5e 0xe66 0x5f 0xe62 0x60 0xe46 0x62 0xe0e 0x63 0xdbd 0x64 0xd48 0x64 0xd48 0x64 0xd48 0x64 0xd48>;
			battery_profile_t3_num = <0x56>;
			battery_profile_t3 = <0x00 0x1129 0x01 0x1126 0x02 0x1110 0x04 0x10ff 0x05 0x10ef 0x06 0x10e0 0x07 0x10d2 0x08 0x10c4 0x09 0x10b5 0x0b 0x10a7 0x0c 0x1099 0x0d 0x108b 0x0e 0x107d 0x0f 0x106f 0x11 0x1061 0x12 0x1053 0x13 0x1045 0x14 0x1038 0x15 0x102a 0x16 0x101d 0x18 0x1010 0x19 0x1003 0x1a 0xff5 0x1b 0xfea 0x1c 0xfdd 0x1e 0xfd1 0x1f 0xfc6 0x20 0xfba 0x21 0xfae 0x22 0xfa3 0x23 0xf99 0x25 0xf8f 0x26 0xf85 0x27 0xf7b 0x28 0xf72 0x29 0xf68 0x2b 0xf5f 0x2c 0xf55 0x2d 0xf49 0x2e 0xf3a 0x2f 0xf2a 0x30 0xf1f 0x32 0xf15 0x33 0xf0e 0x34 0xf07 0x35 0xf01 0x36 0xefb 0x38 0xef4 0x39 0xeef 0x3a 0xeea 0x3b 0xee5 0x3c 0xee1 0x3d 0xedc 0x3f 0xed8 0x40 0xed4 0x41 0xed0 0x42 0xecd 0x43 0xeca 0x45 0xec7 0x46 0xec3 0x47 0xec0 0x48 0xebc 0x49 0xeb6 0x4a 0xeac 0x4c 0xea6 0x4d 0xea2 0x4e 0xe9e 0x4f 0xe99 0x50 0xe94 0x52 0xe90 0x53 0xe8c 0x54 0xe87 0x55 0xe80 0x56 0xe77 0x58 0xe70 0x59 0xe67 0x5a 0xe5e 0x5b 0xe5d 0x5c 0xe5c 0x5d 0xe5b 0x5f 0xe59 0x60 0xe53 0x61 0xe36 0x62 0xdff 0x63 0xdb2 0x64 0xd48>;
			r_profile_t0_num = <0x56>;
			r_profile_t0 = <0x36e 0x1128 0x36e 0x1114 0x385 0x10ff 0x390 0x10ed 0x395 0x10da 0x39a 0x10c8 0x39d 0x10b6 0x3a7 0x10a5 0x3b8 0x1091 0x3dd 0x107a 0x408 0x105d 0x43d 0x103f 0x44f 0x1023 0x44f 0x1011 0x451 0x1003 0x456 0xff6 0x458 0xfe8 0x456 0xfd7 0x44c 0xfc4 0x444 0xfb1 0x43d 0xf9f 0x43b 0xf90 0x43c 0xf82 0x438 0xf75 0x434 0xf68 0x430 0xf5d 0x42a 0xf51 0x426 0xf46 0x428 0xf3b 0x41f 0xf31 0x41e 0xf28 0x419 0xf1f 0x41a 0xf17 0x41c 0xf10 0x41d 0xf09 0x41e 0xf02 0x424 0xefc 0x426 0xef6 0x427 0xef0 0x42b 0xeeb 0x431 0xee6 0x43b 0xee2 0x444 0xede 0x44b 0xeda 0x455 0xed7 0x460 0xed3 0x46c 0xed0 0x478 0xecd 0x481 0xec9 0x48f 0xec5 0x49b 0xec1 0x4ab 0xebd 0x4bb 0xeb8 0x4cd 0xeb3 0x4de 0xead 0x4f3 0xea7 0x508 0xea1 0x51f 0xe99 0x52a 0xe91 0x518 0xe8a 0x50d 0xe85 0x503 0xe81 0x4fb 0xe7e 0x4ee 0xe79 0x4e5 0xe75 0x4df 0xe73 0x4da 0xe71 0x4d3 0xe6e 0x4ca 0xe6a 0x4b9 0xe64 0x4a7 0xe5d 0x47d 0xe4c 0x406 0xe1c 0x406 0xe1c 0x406 0xe1c 0x406 0xe1c 0x406 0xe1c 0x406 0xe1c 0x406 0xe1c 0x406 0xe1c 0x406 0xe1c 0x406 0xe1c 0x406 0xe1c 0x406 0xe1c 0x406 0xe1c 0x406 0xe1c>;
			r_profile_t1_num = <0x56>;
			r_profile_t1 = <0x1f7 0x1129 0x1f7 0x1118 0x1f2 0x1103 0x1f4 0x10f2 0x1f6 0x10e2 0x1f6 0x10d3 0x1f6 0x10c4 0x1f6 0x10b5 0x1f6 0x10a7 0x1f7 0x1099 0x1f6 0x108b 0x1f6 0x107c 0x1f6 0x106e 0x1f6 0x1060 0x1f8 0x1052 0x1f9 0x1045 0x1fa 0x1037 0x1fc 0x102a 0x1fc 0x101c 0x1fc 0x100e 0x1fb 0x1000 0x1fc 0xff4 0x200 0xfe7 0x204 0xfda 0x203 0xfc8 0x1f9 0xfb3 0x1eb 0xf9d 0x1dc 0xf89 0x1ce 0xf78 0x1c8 0xf6b 0x1c2 0xf60 0x1c1 0xf58 0x1c1 0xf4f 0x1c0 0xf47 0x1c1 0xf3f 0x1c2 0xf37 0x1c2 0xf2f 0x1c2 0xf27 0x1c3 0xf20 0x1c5 0xf18 0x1c9 0xf12 0x1cb 0xf0b 0x1cc 0xf04 0x1cd 0xefe 0x1ce 0xef8 0x1d1 0xef2 0x1d3 0xeec 0x1d7 0xee6 0x1d7 0xee1 0x1da 0xedb 0x1dd 0xed6 0x1de 0xed0 0x1e1 0xecb 0x1e3 0xec6 0x1e8 0xec0 0x1eb 0xebb 0x1f0 0xeb6 0x1f7 0xeb0 0x1fd 0xea9 0x202 0xea3 0x20a 0xe9b 0x211 0xe93 0x218 0xe8b 0x218 0xe81 0x21b 0xe7b 0x226 0xe77 0x238 0xe74 0x255 0xe72 0x280 0xe6e 0x2c2 0xe65 0x315 0xe46 0x388 0xe0b 0x388 0xd46 0x388 0xd46 0x388 0xd46 0x388 0xd46 0x388 0xd46 0x388 0xd46 0x388 0xd46 0x388 0xd46 0x388 0xd46 0x388 0xd46 0x388 0xd46 0x388 0xd46 0x388 0xd46 0x388 0xd46>;
			r_profile_t2_num = <0x56>;
			r_profile_t2 = <0x73 0x110d 0x73 0x110c 0x76 0x10fd 0x76 0x10ee 0x75 0x10e0 0x76 0x10d1 0x77 0x10c3 0x75 0x10b4 0x77 0x10a6 0x74 0x1097 0x79 0x108a 0x78 0x107c 0x74 0x106d 0x73 0x105e 0x78 0x1052 0x7a 0x1044 0x7a 0x1035 0x74 0x1026 0x78 0x101a 0x77 0x100c 0x78 0xfff 0x78 0xff2 0x76 0xfe5 0x7d 0xfdc 0x7d 0xfcf 0x7e 0xfc3 0x82 0xfb7 0x81 0xfaa 0x88 0xf9f 0x8c 0xf94 0x8f 0xf8a 0x8e 0xf82 0x92 0xf79 0x94 0xf6f 0x93 0xf63 0x91 0xf57 0x85 0xf48 0x7a 0xf38 0x73 0xf2b 0x71 0xf21 0x75 0xf19 0x75 0xf12 0x70 0xf0a 0x74 0xf04 0x70 0xefd 0x73 0xef9 0x71 0xef3 0x72 0xeee 0x72 0xee9 0x75 0xee5 0x70 0xede 0x73 0xedb 0x74 0xed7 0x7b 0xed4 0x7d 0xed1 0x7c 0xece 0x7e 0xecb 0x81 0xec8 0x85 0xec5 0x82 0xec1 0x7e 0xebc 0x7b 0xeb6 0x7b 0xeb1 0x7a 0xead 0x7a 0xea9 0x7b 0xea3 0x7c 0xea0 0x7b 0xe9c 0x7c 0xe97 0x7d 0xe8f 0x7c 0xe86 0x7d 0xe80 0x7e 0xe78 0x7c 0xe6e 0x7e 0xe6b 0x7f 0xe69 0x87 0xe68 0x89 0xe66 0x94 0xe62 0x8c 0xe46 0x95 0xe0e 0x9e 0xdbd 0xba 0xd44 0xba 0xd44 0xba 0xd44 0xba 0xd44>;
			r_profile_t3_num = <0x56>;
			r_profile_t3 = <0xa2 0x1129 0xa2 0x1126 0x98 0x1110 0x93 0x10ff 0x8f 0x10ef 0x8f 0x10e0 0x8f 0x10d2 0x8f 0x10c4 0x8f 0x10b5 0x8f 0x10a7 0x8f 0x1099 0x8f 0x108b 0x8f 0x107d 0x8f 0x106f 0x8f 0x1061 0x90 0x1053 0x8f 0x1045 0x8f 0x1038 0x90 0x102a 0x90 0x101d 0x8f 0x1010 0x90 0x1003 0x8f 0xff5 0x8f 0xfea 0x8e 0xfdd 0x90 0xfd1 0x91 0xfc6 0x92 0xfba 0x93 0xfae 0x90 0xfa3 0x93 0xf99 0x93 0xf8f 0x95 0xf85 0x98 0xf7b 0x9a 0xf72 0x9d 0xf68 0xa1 0xf5f 0xa4 0xf55 0xa3 0xf49 0x96 0xf3a 0x8b 0xf2a 0x83 0xf1f 0x7e 0xf15 0x7e 0xf0e 0x7b 0xf07 0x7b 0xf01 0x7b 0xefb 0x79 0xef4 0x7a 0xeef 0x7a 0xeea 0x78 0xee5 0x79 0xee1 0x7a 0xedc 0x7a 0xed8 0x7a 0xed4 0x7a 0xed0 0x7b 0xecd 0x7c 0xeca 0x7d 0xec7 0x7e 0xec3 0x7f 0xec0 0x82 0xebc 0x82 0xeb6 0x7b 0xeac 0x78 0xea6 0x79 0xea2 0x7a 0xe9e 0x79 0xe99 0x78 0xe94 0x7a 0xe90 0x7d 0xe8c 0x81 0xe87 0x82 0xe80 0x80 0xe77 0x86 0xe70 0x81 0xe67 0x70 0xe5e 0x72 0xe5d 0x77 0xe5c 0x80 0xe5b 0x90 0xe59 0xbe 0xe53 0x103 0xe36 0x142 0xdff 0x1ba 0xdb2 0x1da 0xd3d>;
			q_max_pos_50_charging = <0x1030>;
			q_max_pos_25_charging = <0xfb0>;
			q_max_pos_0_charging = <0xe0a>;
			q_max_neg_10_charging = <0xd17>;
			q_max_pos_50_h_current_charging = <0xff9>;
			q_max_pos_25_h_current_charging = <0xf95>;
			q_max_pos_0_h_current_charging = <0xd7c>;
			q_max_neg_10_h_current_charging = <0x764>;
			vbat_remove_detection = <0x00>;
		};

		BAT_NOTIFY {
			compatible = "mediatek,bat_notify";
		};

		bat_comm {
			compatible = "mediatek,battery";
			stop_charging_in_takling = <0x01>;
			talking_recharge_voltage = <0xed8>;
			talking_sync_time = <0x3c>;
			mtk_temperature_recharge_support = <0x01>;
			max_charge_temperature = <0x37>;
			max_charge_temperature_minus_x_degree = <0x33>;
			min_charge_temperature = <0x00>;
			min_charge_temperature_plus_x_degree = <0x05>;
			err_charge_temperature = <0xff>;
			v_pre2cc_thres = <0xd48>;
			v_cc2topoff_thres = <0x1068>;
			recharging_voltage = <0x10a4>;
			charging_full_current = <0xbe>;
			config_usb_if = <0x00>;
			usb_charger_current_suspend = <0x00>;
			usb_charger_current_unconfigured = <0x1b58>;
			usb_charger_current_configured = <0xc350>;
			usb_charger_current = <0x29810>;
			ac_charger_current = <0x29810>;
			non_std_ac_charger_current = <0x29810>;
			charging_host_charger_current = <0xfde8>;
			apple_0_5a_charger_current = <0xc350>;
			apple_1_0a_charger_current = <0xfde8>;
			apple_2_1a_charger_current = <0x13880>;
			bat_low_temp_protect_enable = <0x01>;
			v_charger_enable = <0x01>;
			v_charger_max = <0x1964>;
			v_charger_min = <0x1130>;
			onehundred_percent_tracking_time = <0x0a>;
			npercent_tracking_time = <0x14>;
			sync_to_real_tracking_time = <0x3c>;
			v_0percent_tracking = <0xd7a>;
			high_battery_voltage_support = <0x01>;
			usb_charger_input_current = <0xc350>;
			ac_charger_input_current = <0x30d40>;
			non_std_ac_charger_input_current = <0x186a0>;
			ASUS_4_4V_battery_voltage_support = <0x01>;
		};

		dsi_te {
			compatible = "mediatek, dsi_te_1-eint";
			status = "disabled";
		};
	};

	vcorefs {
		compatible = "mediatek,mt6735-vcorefs";
		clocks = <0x03 0x01 0x03 0x30 0x03 0x33>;
		clock-names = "mux_axi\0syspll_d5\0syspll1_d4";
	};

	rf_clock_buffer {
		compatible = "mediatek,rf_clock_buffer";
		mediatek,clkbuf-quantity = <0x04>;
		mediatek,clkbuf-config = <0x02 0x02 0x02 0x02>;
		status = "okay";
	};

	hwmsensor {
		compatible = "mediatek,hwmsensor";
	};

	gsensor {
		compatible = "mediatek,gsensor";
	};

	als_ps {
		compatible = "mediatek,als_ps";
		pinctrl-names = "pin_default\0pin_cfg";
		pinctrl-0 = <0x93>;
		pinctrl-1 = <0x94>;
		status = "okay";
	};

	m_acc_pl {
		compatible = "mediatek,m_acc_pl";
	};

	m_alsps_pl {
		compatible = "mediatek,m_alsps_pl";
	};

	m_batch_pl {
		compatible = "mediatek,m_batch_pl";
	};

	batchsensor {
		compatible = "mediatek,batchsensor";
	};

	gyroscope {
		compatible = "mediatek,gyroscope";
		pinctrl-names = "pin_default\0pin_cfg";
		pinctrl-0 = <0x95>;
		pinctrl-1 = <0x96>;
		status = "okay";
	};

	m_gyro_pl {
		compatible = "mediatek,m_gyro_pl";
	};

	barometer {
		compatible = "mediatek,barometer";
	};

	m_baro_pl {
		compatible = "mediatek,m_baro_pl";
	};

	msensor {
		compatible = "mediatek,msensor";
	};

	m_mag_pl {
		compatible = "mediatek,m_mag_pl";
	};

	orientation {
		compatible = "mediatek,orientation";
	};

	als {
		compatible = "mediatek, als-eint";
		interrupt-parent = <0x0c>;
		interrupts = <0x4d 0x08>;
		debounce = <0x4d 0x00>;
		status = "okay";
	};

	audio_switch {
		compatible = "mediatek,audio_switch";
	};

	gse_1 {
		compatible = "mediatek, gse_1-eint";
		status = "disabled";
	};

	ext_buck_oc {
		compatible = "mediatek, ext_buck_oc-eint";
		status = "disabled";
	};

	mt8193ckgen@0 {
		compatible = "mediatek,mt8193-ckgen";
		pinctrl-names = "default\0bus_switch_gpio\0bus_switch_dpi";
		pinctrl-0 = <0x97>;
		pinctrl-1 = <0x98>;
		pinctrl-2 = <0x99>;
		bus_switch_pin = <0x0b 0x00 0x00>;
		status = "okay";
	};

	multibridge {
		compatible = "mediatek,multibridge";
	};

	trusty {
		compatible = "android,trusty-smc-v1";
		ranges;
		#address-cells = <0x02>;
		#size-cells = <0x02>;

		irq {
			compatible = "android,trusty-irq-v1";
			ppi-interrupt-parent = <0x01>;
		};

		log {
			compatible = "android,trusty-log-v1";
		};

		virtio {
			compatible = "android,trusty-virtio-v1";
		};

		mtee {
			compatible = "mediatek,trusty-mtee-v1";
		};
	};

	memory@40000000 {
		device_type = "memory";
		reg = <0x00 0x40000000 0x00 0x1f000000>;
	};

	led@0 {
		compatible = "mediatek,red";
		led_mode = <0x03>;
		data = <0x01>;
		pwm_config = <0x00 0x00 0x00 0x00 0x00>;
	};

	led@1 {
		compatible = "mediatek,green";
		led_mode = <0x03>;
		data = <0x02>;
		pwm_config = <0x00 0x00 0x00 0x00 0x00>;
	};

	led@2 {
		compatible = "mediatek,blue";
		led_mode = <0x00>;
		data = <0x01>;
		pwm_config = <0x00 0x00 0x00 0x00 0x00>;
	};

	led@3 {
		compatible = "mediatek,jogball-backlight";
		led_mode = <0x00>;
		data = <0x01>;
		pwm_config = <0x00 0x00 0x00 0x00 0x00>;
	};

	led@4 {
		compatible = "mediatek,keyboard-backlight";
		led_mode = <0x00>;
		data = <0x01>;
		pwm_config = <0x00 0x00 0x00 0x00 0x00>;
	};

	led@5 {
		compatible = "mediatek,button-backlight";
		led_mode = <0x00>;
		data = <0x01>;
		pwm_config = <0x00 0x00 0x00 0x00 0x00>;
	};

	led@6 {
		compatible = "mediatek,lcd-backlight";
		led_mode = <0x05>;
		data = <0x01>;
		pwm_config = <0x00 0x00 0x00 0x00 0x00>;
	};

	vibrator@0 {
		compatible = "mediatek,vibrator";
		vib_timer = <0x19>;
		vib_limit = <0x09>;
		vib_vol = <0x06>;
	};

	cust_accel@0 {
		compatible = "mediatek,kxtj2_1009";
		i2c_num = <0x02>;
		i2c_addr = <0x0e 0x00 0x00 0x00>;
		direction = <0x05>;
		power_id = <0xffff>;
		power_vol = <0x00>;
		firlen = <0x00>;
		is_batch_supported = <0x00>;
	};

	cust_accel@1 {
		compatible = "mediatek,n2dm";
		i2c_num = <0x02>;
		i2c_addr = <0x08 0x00 0x00 0x00>;
		direction = <0x05>;
		power_id = <0xffff>;
		power_vol = <0x00>;
		firlen = <0x06>;
		is_batch_supported = <0x00>;
	};

	cust_alsps@0 {
		compatible = "mediatek,epl259x";
		i2c_num = <0x02>;
		i2c_addr = <0x49 0x00 0x00 0x00>;
		polling_mode_ps = <0x00>;
		polling_mode_als = <0x01>;
		power_id = <0xffff>;
		power_vol = <0x00>;
		als_level = <0x46 0xa0 0x104 0x25d 0x3f2 0x564 0x6e0 0x834 0xa28 0xfa0 0x157c 0x1b58 0x2328 0x3a98 0x4e20>;
		als_value = <0x00 0x32 0x64 0x104 0x190 0x208 0x2bc 0x352 0x41a 0x60e 0xbb8 0x1388 0x1b58 0x2328 0x4e20 0x4e20>;
		ps_threshold_high = <0x320>;
		ps_threshold_low = <0x1f4>;
		is_batch_supported_ps = <0x00>;
		is_batch_supported_als = <0x00>;
	};

	cust_mag@0 {
		compatible = "mediatek,mmc3524x";
		i2c_num = <0x02>;
		i2c_addr = <0x30 0x00 0x00 0x00>;
		direction = <0x07>;
		power_id = <0xffff>;
		power_vol = <0x00>;
		is_batch_supported = <0x00>;
	};

	cust_mag@1 {
		compatible = "mediatek,qmcX983";
		i2c_num = <0x02>;
		i2c_addr = <0x2c 0x00 0x00 0x00>;
		direction = <0x04>;
		power_id = <0xffff>;
		power_vol = <0x00>;
		is_batch_supported = <0x00>;
	};

	cust_gyro@0 {
		compatible = "mediatek,itg1010";
		i2c_num = <0x02>;
		i2c_addr = <0x68 0x00 0x00 0x00>;
		direction = <0x03>;
		power_id = <0xffff>;
		power_vol = <0x00>;
		firlen = <0x00>;
		is_batch_supported = <0x00>;
	};

	flashlight@ {
		compatible = "mediatek,flashlight";
		pinctrl-names = "default\0state_enable_output0\0state_enable_output1\0state_mode_output0\0state_mode_output1\0state_pwm_output\0charger_red_GPIO_output";
		pinctrl-0 = <0x9a>;
		pinctrl-1 = <0x9b>;
		pinctrl-2 = <0x9c>;
		pinctrl-3 = <0x9d>;
		pinctrl-4 = <0x9e>;
		pinctrl-5 = <0x9f>;
		pinctrl-6 = <0xa0>;
		status = "okay";
	};

	sim1_hot_plug {
		compatible = "mediatek,sim1_hot_plug";
		status = "okay";
	};

	sim2_hot_plug {
		compatible = "mediatek,sim2_hot_plug";
		status = "okay";
	};

	mse {
		compatible = "mediatek,mse";
		status = "okay";
		interrupt-parent = <0x0c>;
		interrupts = <0x3d 0x08>;
		debounce = <0x3d 0x00>;
	};

	chr_stat {
		compatible = "mediatek,chr_stat";
		status = "okay";
		interrupt-parent = <0x0c>;
		interrupts = <0x7e 0x08>;
		debounce = <0x7e 0x00>;
	};

	fpreset {
		compatible = "mediatek,fpreset";
		pinctrl-names = "spi_default\0finger_rst_low\0finger_rst_high";
		pinctrl-0 = <0xa1>;
		pinctrl-1 = <0xa2>;
		pinctrl-2 = <0xa3>;
		status = "okay";
	};

	finger_print@0 {
		compatible = "mediatek,finger_print-eint";
		finger_int_pin = <0x79 0x00>;
		status = "okay";
		interrupt-parent = <0x0c>;
		interrupts = <0x79 0x01>;
		debounce = <0x79 0x00>;
	};

	finger {
		compatible = "mediatek,afs121";
		pinctrl-names = "spi_default\0spi_cs_low\0spi_cs_high\0spi_mi_low\0spi_mi_high\0spi_mo_low\0spi_mo_high\0spi_mclk_low\0spi_mclk_high\0finger_rst_low\0finger_rst_high\0eint\0eint_in_low\0eint_in_float";
		pinctrl-0 = <0xa1>;
		pinctrl-1 = <0xa4>;
		pinctrl-2 = <0xa5>;
		pinctrl-3 = <0xa6>;
		pinctrl-4 = <0xa7>;
		pinctrl-5 = <0xa8>;
		pinctrl-6 = <0xa9>;
		pinctrl-7 = <0xaa>;
		pinctrl-8 = <0xab>;
		pinctrl-9 = <0xa2>;
		pinctrl-10 = <0xa3>;
		pinctrl-11 = <0xac>;
		pinctrl-12 = <0xad>;
		pinctrl-13 = <0xae>;
		status = "okay";
	};
};
